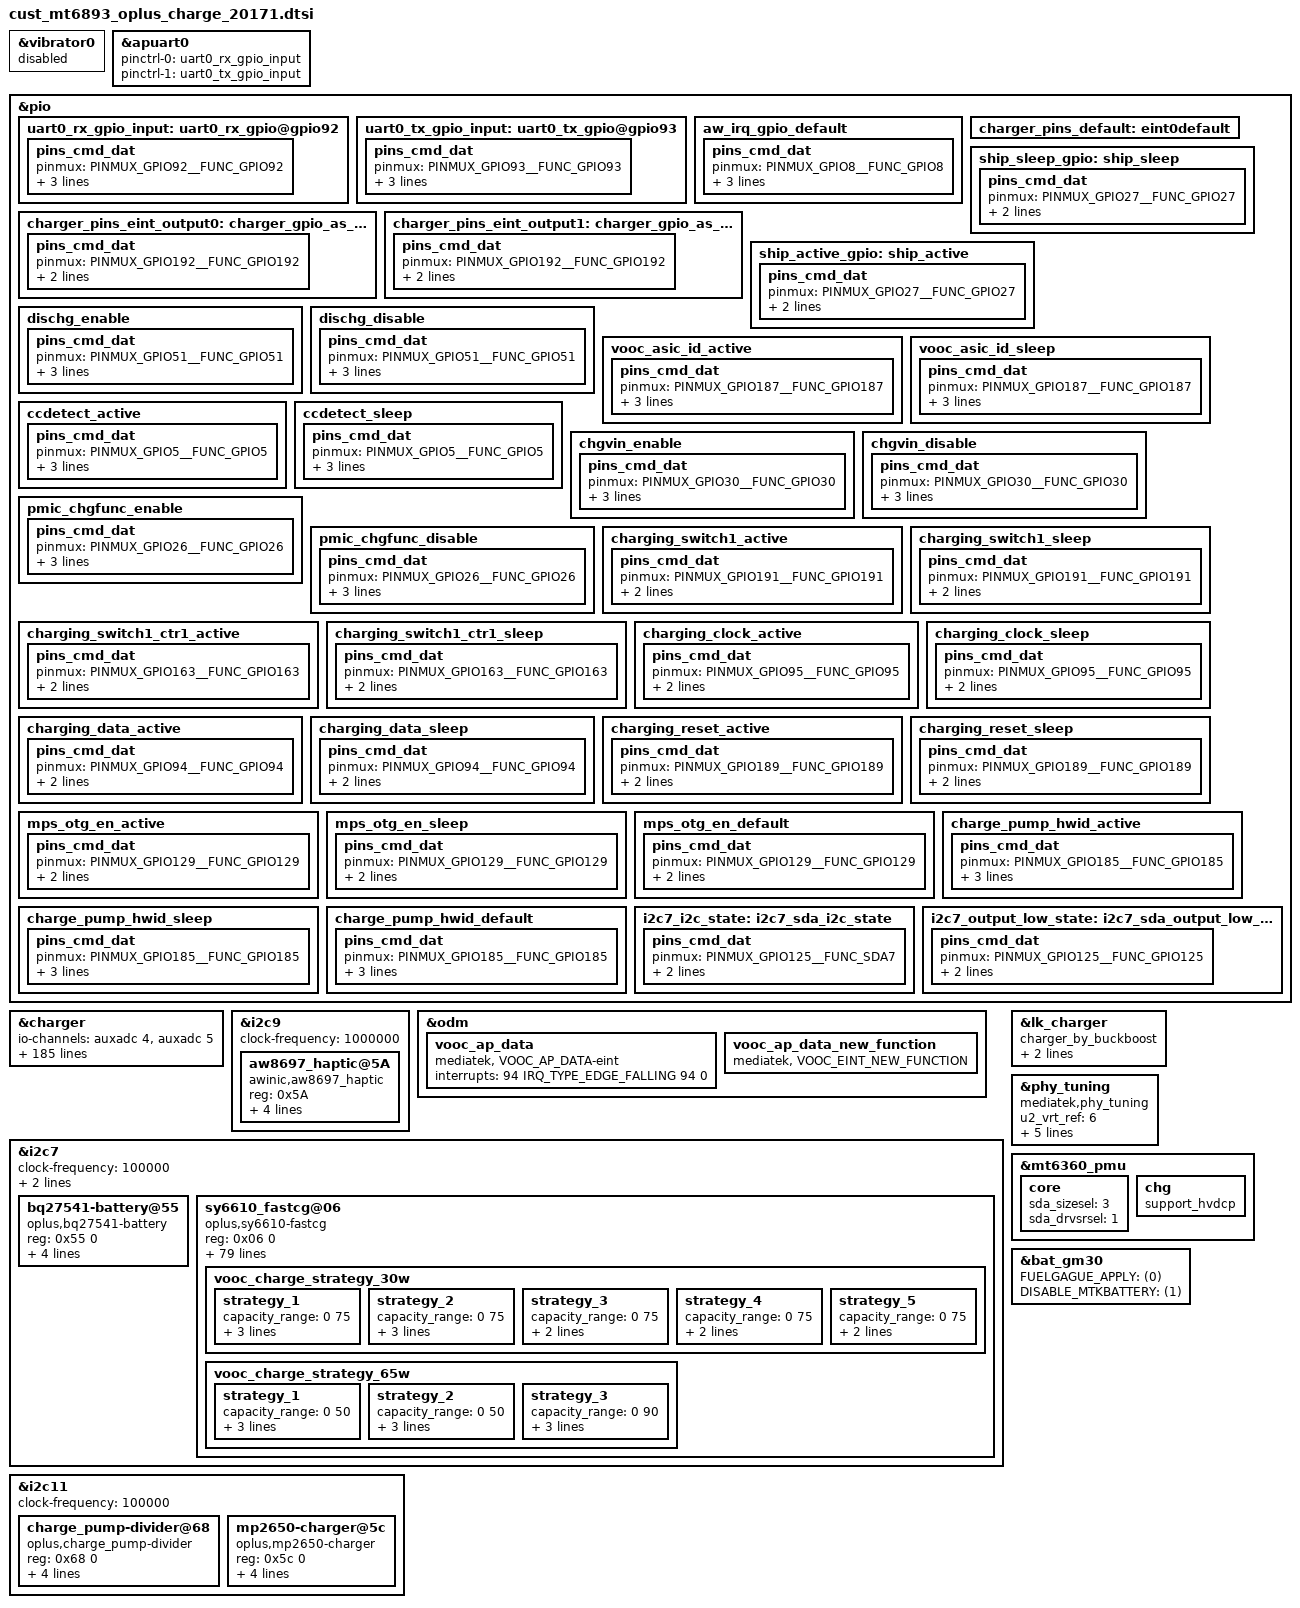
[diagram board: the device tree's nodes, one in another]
// SPDX-License-Identifier: GPL-2.0-only
/*
* Copyright (C) 2021-2020 Oplus. All rights reserved.
*/

/* charge start */
&vibrator0 {
	status = "disabled";
};

&apuart0 {
	pinctrl-names = "uart0_rx_gpio", "uart0_tx_gpio";
	pinctrl-0 = <&uart0_rx_gpio_input>;
	pinctrl-1 = <&uart0_tx_gpio_input>;
	status = "okay";
};

&pio {
	uart0_rx_gpio_input:uart0_rx_gpio@gpio92 {
		pins_cmd_dat {
			pinmux = <PINMUX_GPIO92__FUNC_GPIO92>;
			input-enable;
			slew-rate = <0>;
			bias-disable;
		};
	};

	uart0_tx_gpio_input:uart0_tx_gpio@gpio93 {
		pins_cmd_dat {
			pinmux = <PINMUX_GPIO93__FUNC_GPIO93>;
			input-enable;
			slew-rate = <0>;
			bias-disable;
		};
	};
};

&charger {
	io-channels = <&auxadc 4>,
		<&auxadc 5>;
	io-channel-names = "auxadc4-usb_temp_v_l",
		"auxadc5-usb_temp_v_r";

	pinctrl-names = "default", "charger_gpio_as_output_low", "charger_gpio_as_output_high", "ship_sleep", "ship_active",
		"dischg_enable", "dischg_disable", "chgvin_enable", "chgvin_disable", "pmic_chgfunc_enable", "pmic_chgfunc_disable",
		"ccdetect_active","ccdetect_sleep";
	pinctrl-0 = <&charger_pins_default>;
	pinctrl-1 = <&charger_pins_eint_output0>;		//USB_ON -> USB_SWITCH:(UART && USB)
	pinctrl-2 = <&charger_pins_eint_output1>;
	pinctrl-3 = <&ship_sleep_gpio>;
	pinctrl-4 = <&ship_active_gpio>;
	pinctrl-5 = <&dischg_enable>;
	pinctrl-6 = <&dischg_disable>;
	pinctrl-7 = <&chgvin_enable>;
	pinctrl-8 = <&chgvin_disable>;
	pinctrl-9 = <&pmic_chgfunc_enable>;
	pinctrl-10 = <&pmic_chgfunc_disable>;
	//pinctrl-5 = <&shortc_active_gpio>;
	pinctrl-11 = <&ccdetect_active>;
	pinctrl-12 = <&ccdetect_sleep>;

	qcom,hv_flashled_support;
	qcom,chargerid_support;
	qcom,smart_charging_screenoff;
	qcom,usbtemp_batttemp_gap = <18>;
	qcom,input_current_charger_ma = <2000>;
	qcom,pd_input_current_charger_ma = <2000>;
	qcom,qc_input_current_charger_ma = <2000>;
	qcom,input_current_usb_ma = <500>;

	qcom,input_current_led_ma = <1200>;
	qcom,input_current_led_ma_high = <1200>;
	qcom,input_current_led_ma_warm = <1500>;
	qcom,input_current_led_ma_normal = <2000>;
	qcom,led_warm_bat_decidegc = <350>;
	qcom,led_high_bat_decidegc = <370>;

	qcom,input_current_camera_ma = <1200>;
	qcom,input_current_cdp_ma = <1500>;

	qcom,input_current_vooc_led_ma_high = <1200>;
	qcom,input_current_vooc_led_ma_warm = <1800>;
	qcom,input_current_vooc_led_ma_normal = <3600>;
	qcom,input_current_vooc_ma_normal = <3600>;
	qcom,vooc_temp_bat_normal_decidegc = <350>;
	qcom,input_current_vooc_ma_warm = <3200>;
	qcom,vooc_temp_bat_warm_decidegc = <370>;
	qcom,input_current_vooc_ma_high = <2200>;
	qcom,vooc_temp_bat_hot_decidegc = <440>;

	qcom,charger_current_vooc_ma_normal = <1800>;

	qcom,chg_ctrl_by_calling;
	qcom,input_current_calling_ma = <1500>;

	qcom,overtemp_bat_decidegc = <350>;
	qcom,iterm_disabled = <0>;
	sw_full_count = <25>;
	qcom,iterm_ma = <120>;
	qcom,recharge-mv = <100>;
	qcom,batt_capacity_mah = <4500>;/*typical capacity*/

	qcom,removed_bat_decidegc = <190>;  /*<-19C*/

	qcom,cold_bat_decidegc = <20>;  /*-2C~0C*/
	qcom,temp_cold_vfloat_mv = <3980>;
	qcom,temp_cold_fastchg_current_ma = <300>;

	qcom,little_cold_bat_decidegc = <0>;    /*0C~5C*/
	qcom,temp_little_cold_vfloat_mv = <4435>;
	qcom,temp_little_cold_fastchg_current_ma_high = <1100>;
	qcom,temp_little_cold_fastchg_current_ma_low = <1100>;
	qcom,temp_little_cold_fastchg_current_ma = <1100>;
	qcom,pd_temp_little_cold_fastchg_current_ma_high = <2000>;
	qcom,pd_temp_little_cold_fastchg_current_ma_low = <1400>;
	qcom,qc_temp_little_cold_fastchg_current_ma_high = <2000>;
	qcom,qc_temp_little_cold_fastchg_current_ma_low = <1400>;

	qcom,cool_bat_decidegc = <50>;  /*5C~12C*/
	qcom,temp_cool_vfloat_mv = <4435>;
	qcom,temp_cool_fastchg_current_ma_high = <1100>;
	qcom,temp_cool_fastchg_current_ma_low = <1100>;
	qcom,pd_temp_cool_fastchg_current_ma_high = <2000>;
	qcom,pd_temp_cool_fastchg_current_ma_low = <2000>;
	qcom,qc_temp_cool_fastchg_current_ma_high = <2000>;
	qcom,qc_temp_cool_fastchg_current_ma_low = <2000>;

	qcom,little_cool_bat_decidegc = <120>;  /*12C~16C*/
	qcom,temp_little_cool_vfloat_mv = <4435>;
	qcom,temp_little_cool_fastchg_current_ma = <1100>;
	qcom,pd_temp_little_cool_fastchg_current_ma = <2000>;
	qcom,qc_temp_little_cool_fastchg_current_ma = <2000>;

	qcom,normal_bat_decidegc = <160>;       /*16C~45C*/
	qcom,temp_normal_vfloat_mv = <4435>;
	qcom,temp_normal_fastchg_current_ma = <1100>;
	qcom,pd_temp_normal_fastchg_current_ma = <2000>;
	qcom,qc_temp_normal_fastchg_current_ma = <2000>;

	qcom,warm_bat_decidegc = <450>;         /*45C~53C*/ /*8pin Bat Vooc project need add 3 degree C*/
	qcom,temp_warm_vfloat_mv = <4130>;
	qcom,temp_warm_fastchg_current_ma = <600>;
	qcom,pd_temp_warm_fastchg_current_ma = <600>;
	qcom,qc_temp_warm_fastchg_current_ma = <600>;
	qcom,temp_warm_fastchg_current_ma_led_on = <250>;

	qcom,hot_bat_decidegc = <530>;

	qcom,non_standard_vfloat_mv = <3980>;
	qcom,non_standard_fastchg_current_ma = <512>;

	qcom,short_c_bat_cv_mv = <4330>;
	qcom,short_c_bat_vfloat_mv = <3800>;
	qcom,short_c_bat_fastchg_current_ma = <512>;

	qcom,cold_vfloat_sw_limit = <3930>;
	qcom,little_cold_vfloat_sw_limit = <4385>;
	qcom,cool_vfloat_sw_limit = <4385>;
	qcom,little_cool_vfloat_sw_limit = <4385>;
	qcom,normal_vfloat_sw_limit = <4385>;
	qcom,warm_vfloat_sw_limit = <4080>;
	qcom,non_standard_vfloat_sw_limit = <3930>;
	qcom,short_c_bat_vfloat_sw_limit = <3750>;

	qcom,max_chg_time_sec = <63360>; // 2200 * 2 / 250 H
	qcom,charger_hv_thr = <9900>;
	qcom,charger_recv_thr = <9500>;
	qcom,charger_lv_thr = <3400>;
	qcom,vbatt_full_thr = <4435>;
	qcom,vbatt_hv_thr = <4600>;

	qcom,vfloat_step_mv = <8>;
	qcom,non_standard_vfloat_over_sw_limit = <3990>;
	qcom,cold_vfloat_over_sw_limit = <3990>;
	qcom,little_cold_vfloat_over_sw_limit = <4445>;
	qcom,cool_vfloat_over_sw_limit = <4445>;
	qcom,little_cool_vfloat_over_sw_limit = <4445>;
	qcom,normal_vfloat_over_sw_limit = <4445>;
	qcom,warm_vfloat_over_sw_limit = <4140>;

	qcom,vbatt_power_off = <3300>;
	qcom,vbatt_soc_1 = <3310>;
	qcom,vooc_project = <3>;
	qcom,vbatt_num = <2>;
	qcom,new_ui_warning_support;
	qcom,ffc_support;
	qcom,dual_ffc;
	recharge_after_full;

	qcom,normal_vterm_hw_inc = <18>;
	qcom,non_normal_vterm_hw_inc = <18>;

	qcom,ff1_normal_fastchg_ma = <550>;
	qcom,ff1_warm_fastchg_ma = <550>;

	qcom,ffc2_normal_fastchg_ma = <350>;/*12C~35c*/
	qcom,ffc2_temp_warm_decidegc = <350>;
	qcom,ffc2_warm_fastchg_ma = <350>;/*35C~40c*/
	qcom,ffc2_temp_high_decidegc = <400>;
	qcom,ffc2_temp_low_decidegc = <120>;

	qcom,ff1_exit_step_ma = <150>;
	qcom,ff1_warm_exit_step_ma = <150>;
	qcom,ffc2_exit_step_ma = <150>;
	qcom,ffc2_warm_exit_step_ma = <150>;

	qcom,ffc_normal_vfloat_sw_limit = <4445>;
	qcom,ffc_temp_normal_vfloat_mv = <4500>;
	qcom,ffc_normal_vfloat_over_sw_limit = <4500>;
	qcom,ffc_warm_vfloat_sw_limit = <4445>;
	qcom,ffc_temp_warm_vfloat_mv = <4500>;
	qcom,ffc_warm_vfloat_over_sw_limit = <4500>;

	qcom,ffc2_normal_vfloat_sw_limit = <4440>;
	qcom,ffc2_temp_normal_vfloat_mv = <4500>;
	qcom,ffc2_normal_vfloat_over_sw_limit = <4500>;
	qcom,ffc2_warm_vfloat_sw_limit = <4435>;
	qcom,ffc2_temp_warm_vfloat_mv = <4500>;
	qcom,ffc2_warm_vfloat_over_sw_limit = <4500>;

	qcom,default_iterm_ma = <120>;
	qcom,default_temp_normal_fastchg_current_ma = <1100>;
	qcom,default_normal_vfloat_sw_limit = <4385>;
	qcom,default_temp_normal_vfloat_mv = <4435>;
	qcom,default_normal_vfloat_over_sw_limit = <4445>;

	qcom,default_temp_little_cool_fastchg_current_ma = <1100>;
	qcom,default_little_cool_vfloat_sw_limit = <4385>;
	qcom,default_temp_little_cool_vfloat_mv = <4435>;
	qcom,default_little_cool_vfloat_over_sw_limit = <4445>;

	qcom,vooc_show_ui_soc_decimal;
	qcom,ui_soc_decimal_speedmin = <20>;//2A
	qcom,check_batt_full_by_sw;
	qcom,external_gauge;
	qcom,chg_ctrl_by_lcd;
	qcom,chg_ctrl_by_vooc;
	qcom,chg_ctrl_by_camera;
	qcom,support_ntc_01c_precision;
	qcom,sw_vfloat_over_protect_enable;

	qcom,support_abnormal_adapter;

	//for PD9V or QC9V
	qcom,vbatt_pdqc_to_5v_thr = <4100>;
	qcom,vbatt_pdqc_to_9v_thr = <4000>;

	//GPIO config:
	qcom,chargerid_switch-gpio = <&pio 192 0x00>;
	qcom,ship-gpio = <&pio 27 0x00>;
	qcom,dischg-gpio = <&pio 51 0x00>;
	//qcom,shortc-gpio = <&pio 121 0x00>;
	qcom,ccdetect-gpio = <&pio 5 0x00>;
	qcom,chgvin = <&pio 30 0x00>;
	qcom,pmic_chgfunc = <&pio 26 0x00>;
};

&i2c9 {
	status = "okay";
	clock-frequency = <1000000>;

	/* AWINIC AW8697 Haptic */
	aw8697_haptic@5A {
		status = "okay";
		compatible = "awinic,aw8697_haptic";
		reg = <0x5A>;
		reset-gpio = <&pio 110 0x00>;
		irq-gpio = <&pio 8 0x00>;
		qcom,device_id = <815>;

		pinctrl-names = "default";
		pinctrl-0 = <&aw_irq_gpio_default>;
	};
};

&pio{
	aw_irq_gpio_default: aw_irq_gpio_default {
		pins_cmd_dat {
			pinmux = <PINMUX_GPIO8__FUNC_GPIO8>;
			input-enable;
			slew-rate = <0>;
			bias-pull-up;
		};
	};
};

&odm {
	vooc_ap_data:vooc_ap_data {
		compatible = "mediatek, VOOC_AP_DATA-eint";
		interrupts = <94 IRQ_TYPE_EDGE_FALLING 94 0>;
	};
	vooc_ap_data_new_function:vooc_ap_data_new_function {
		compatible = "mediatek, VOOC_EINT_NEW_FUNCTION";
	};
};

&i2c7 {
	status = "okay";
	clock-frequency = <100000>;

	bq27541-battery@55 {
		status = "okay";
		compatible = "oplus,bq27541-battery";
		reg = <0x55 0>;
		qcom,modify-soc-smooth;
		qcom,modify-soc-calibration;
		qcom,batt_bq28z610;
		qcom,sha1_key_index = <1>;
		//qcom,bq28z610_need_balancing;
	};

	sy6610_fastcg@06{
		status = "okay";
		compatible = "oplus,sy6610-fastcg";
		reg = <0x06 0>;
		qcom,oplus_batt_4250mv;
		qcom,support_vooc_by_normal_charger_path;
		//qcom,vooc_fw_update_newmethod;
		qcom,vooc-fw-type = <3>;
		qcom,vooc_reply_mcu_bits = <7>;
		qcom,vooc-low-temp = <0>;
		qcom,vooc-high-temp = <430>;
		qcom,vooc-low-soc = <1>;
		qcom,vooc-high-soc = <90>;
		qcom,vooc-little-cool-temp = <160>;
		qcom,vooc-cool-temp = <120>;
		qcom,vooc-little-cool-to-normal-temp = <180>;
		qcom,vooc-normal-to-little-cool-current = <0x05>;//5A

		qcom,vooc_cool_bat_volt = <3450>;
		qcom,vooc_little_cool_bat_volt = <3400>;
		qcom,vooc_normal_bat_volt = <3350>;
		qcom,vooc_warm_bat_volt = <3300>;

		qcom,vooc_cool_bat_suspend_volt = <3450>;
		qcom,vooc_little_cool_bat_suspend_volt = <3400>;
		qcom,vooc_normal_bat_suspend_volt = <3350>;
		qcom,vooc_warm_bat_suspend_volt = <3300>;

		qcom,vooc_multistep_adjust_current_support;
		qcom,vooc_multistep_initial_batt_temp = <1000>;
		qcom,vooc_strategy_normal_current = <0x0c>;
		qcom,vooc_batt_over_high_temp = <440>;
		qcom,vooc_batt_over_low_temp = <45>;
		qcom,vooc_over_high_or_low_current = <0x0>;

		qcom,vooc_strategy1_batt_high_temp0 = <400>;
		qcom,vooc_strategy1_batt_high_temp1 = <420>;
		qcom,vooc_strategy1_batt_high_temp2 = <430>;
		qcom,vooc_strategy1_batt_low_temp2 = <420>;
		qcom,vooc_strategy1_batt_low_temp1 = <410>;
		qcom,vooc_strategy1_batt_low_temp0 = <390>;

		qcom,vooc_strategy1_high_current0 = <0x09>;  // 5A
		qcom,vooc_strategy1_high_current1 = <0x07>;  // 4A
		qcom,vooc_strategy1_high_current2 = <0x05>;  // 3A
		qcom,vooc_strategy1_low_current2 = <0x07>;   // 4A
		qcom,vooc_strategy1_low_current1 = <0x09>;   // 5A
		qcom,vooc_strategy1_low_current0 = <0x0c>;   // 0x0c

		qcom,vooc_strategy2_batt_up_temp1 = <375>;
		qcom,vooc_strategy2_batt_up_down_temp2 = <380>;
		qcom,vooc_strategy2_batt_up_temp3 = <390>;
		qcom,vooc_strategy2_batt_up_down_temp4 = <400>;
		qcom,vooc_strategy2_batt_up_temp5 = <410>;
		qcom,vooc_strategy2_batt_up_temp6 = <415>;
		qcom,vooc_strategy2_high0_current = <0x09>;
		qcom,vooc_strategy2_high1_current = <0x07>;
		qcom,vooc_strategy2_high2_current = <0x05>;
		qcom,vooc_strategy2_high3_current = <0x03>;

		qcom,abnormal_adapter_current = <0x00 0x00 0x09 0x09 0x07 0x07 0x05 0x05 0x03 0x03>;

		qcom,vooc_current_lvl = <1000
									1500
									2000
									2500
									3000
									3500
									4000
									4500
									5000
									5500
									6000
									6500
									7000
									7500
									8000
									8500
									9000
									9500
									10000
									10500
									11000
									11500
									12000
									12500>;
		pinctrl-names = "switch1_act_switch2_act", "switch1_sleep_switch2_sleep",
						"switch1_act_switch3_act", "switch1_sleep_switch3_sleep",
						"switch1_act_switch2_sleep", "switch1_sleep_switch2_act",
						"clock_active","clock_sleep",
						"data_active","data_sleep",
						"reset_active","reset_sleep",
						"charging_switch1_ctr1_active","charging_switch1_ctr1_sleep",
						"vooc_asic_id_active","vooc_asic_id_sleep";
		pinctrl-0 = <&charging_switch1_active>;
		pinctrl-1 = <&charging_switch1_sleep>;
		pinctrl-2 = <&charging_switch1_active>;
		pinctrl-3 = <&charging_switch1_sleep>;
		pinctrl-4 = <&charging_switch1_active>;
		pinctrl-5 = <&charging_switch1_sleep>;
		pinctrl-6 = <&charging_clock_active>;
		pinctrl-7 = <&charging_clock_sleep>;
		pinctrl-8 = <&charging_data_active>;
		pinctrl-9 = <&charging_data_sleep>;
		pinctrl-10 = <&charging_reset_active>;
		pinctrl-11 = <&charging_reset_sleep>;
		pinctrl-12 = <&charging_switch1_ctr1_active>;
		pinctrl-13 = <&charging_switch1_ctr1_sleep>;
		pinctrl-14 = <&vooc_asic_id_active>;
		pinctrl-15 = <&vooc_asic_id_sleep>;

		qcom,charging_switch1-gpio = <&pio 191 0x00>;
		qcom,charging_switch1_ctr1-gpio = <&pio 163 0x00>;
		//qcom,charging_switch2-gpio = <&tlmm 113 0x00>;
		//qcom,charging_switch3-gpio = <&tlmm 38 0x00>;

		qcom,charging_reset-gpio = <&pio 189 0x00>;
		qcom,charging_clock-gpio = <&pio 95 0x00>;
		qcom,charging_data-gpio = <&pio 94 0x00>;
		qcom,vooc_asic_id-gpio = <&pio 187 0x00>;

		qcom,parse_fw_from_dt;
		vooc,firmware_data = [
			20 05 00 20 d5 00 00 00 cb 02 00 00 f5 01 00 00
			00 00 00 00 00 00 00 00 00 00 00 00 00 00 00 00
			00 00 00 00 00 00 00 00 00 00 00 00 e1 00 00 00
			00 00 00 00 00 00 00 00 e3 00 00 00 cd 03 00 00
			e7 00 00 00 e9 00 00 00 eb 00 00 00 ed 00 00 00
			ef 00 00 00 f1 00 00 00 f3 00 00 00 f5 00 00 00
			d9 23 00 00 ed 23 00 00 fb 00 00 00 fd 00 00 00
			ff 00 00 00 01 01 00 00 03 01 00 00 89 2c 00 00
			07 01 00 00 25 1f 00 00 91 24 00 00 4d 2e 00 00
			0f 01 00 00 11 01 00 00 13 01 00 00 15 01 00 00
			17 01 00 00 19 01 00 00 1d 01 00 00 1d 01 00 00
			1f 01 00 00 21 01 00 00 23 01 00 00 25 01 00 00
			03 48 85 46 00 f0 84 f8 00 48 00 47 59 25 00 00
			20 05 00 20 14 48 80 47 14 48 00 47 fe e7 fe e7
			fe e7 fe e7 fe e7 fe e7 fe e7 fe e7 fe e7 fe e7
			fe e7 fe e7 fe e7 fe e7 fe e7 fe e7 fe e7 fe e7
			fe e7 fe e7 fe e7 fe e7 fe e7 fe e7 fe e7 fe e7
			fe e7 fe e7 fe e7 fe e7 fe e7 fe e7 fe e7 fe e7
			fe e7 fe e7 fe e7 00 00 e5 03 00 00 c1 00 00 00
			30 b5 0b 46 01 46 00 20 20 22 01 24 09 e0 0d 46
			d5 40 9d 42 05 d3 1d 46 95 40 49 1b 25 46 95 40
			40 19 15 46 52 1e 00 2d f1 dc 30 bd 70 b5 00 24
			25 46 00 28 01 da 01 24 40 42 00 29 01 da 01 25
			49 42 ff f7 dd ff ac 42 00 d0 40 42 00 2c 00 d0
			49 42 70 bd d2 b2 01 e0 02 70 40 1c 49 1e fb d2
			70 47 00 22 f6 e7 10 b5 13 46 0a 46 04 46 19 46
			ff f7 f0 ff 20 46 10 bd 03 21 00 1d 40 1e 03 78
			12 02 1a 43 49 1e f9 d5 10 46 70 47 03 46 03 22
			08 70 00 0a 49 1c 52 1e fa d5 18 46 70 47 00 00
			06 4c 01 25 06 4e 05 e0 e3 68 07 cc 2b 43 0c 3c
			98 47 10 34 b4 42 f7 d3 ff f7 6e ff 78 34 00 00
			98 34 00 00 04 20 71 46 08 42 02 d1 ef f3 08 80
			01 e0 ef f3 09 80 00 00 00 4a 10 47 8d 02 00 00
			00 20 03 49 09 68 01 22 12 03 11 40 08 0b 70 47
			00 00 01 40 10 b5 01 f0 cf fe 04 46 10 20 20 40
			00 28 17 d0 04 20 01 f0 91 fe 10 48 00 68 00 28
			07 d1 02 f0 93 fe 00 20 0d 49 08 70 01 20 0b 49
			08 60 0c 48 00 78 02 28 02 d1 00 f0 4d fc 01 e0
			01 f0 0c f8 01 20 80 02 20 40 00 28 05 d0 0a 20
			01 f0 74 fe 01 20 04 49 08 70 10 bd a0 00 00 20
			64 00 00 20 8b 00 00 20 3d 00 00 20 00 bf fe e7
			f8 b5 04 46 0d 46 16 46 33 46 2a 46 21 46 55 20
			01 f0 b4 fe 07 46 38 46 f8 bd f8 b5 05 46 14 46
			20 78 61 78 09 02 08 43 06 46 32 46 29 46 55 20
			01 f0 a0 ff 07 46 38 46 f8 bd 70 47 00 bf 72 b6
			00 bf 05 48 00 69 01 21 09 03 88 43 02 49 08 61
			00 bf 62 b6 00 bf 70 47 00 00 01 40 06 48 40 68
			01 21 09 03 88 43 04 49 48 60 08 46 00 69 89 14
			08 43 01 49 08 61 70 47 00 00 01 40 00 bf 72 b6
			00 bf 05 48 00 69 01 21 09 03 88 43 02 49 08 61
			00 bf 62 b6 00 bf 70 47 00 00 01 40 03 48 00 69
			01 21 09 03 88 43 01 49 08 61 70 47 00 00 01 40
			00 bf 72 b6 00 bf 05 48 00 69 01 21 c9 02 88 43
			02 49 08 61 00 bf 62 b6 00 bf 70 47 00 00 01 40
			00 bf 72 b6 00 bf 08 48 40 68 01 21 c9 02 88 43
			05 49 48 60 08 46 00 69 c9 14 08 43 02 49 08 61
			00 bf 62 b6 00 bf 70 47 00 00 01 40 06 48 40 68
			01 21 c9 02 88 43 04 49 48 60 08 46 00 69 c9 14
			08 43 01 49 08 61 70 47 00 00 01 40 00 bf 72 b6
			00 bf 05 48 00 69 01 21 c9 02 88 43 02 49 08 61
			00 bf 62 b6 00 bf 70 47 00 00 01 40 04 48 00 68
			00 28 04 d0 02 48 00 68 40 1e 01 49 08 60 70 47
			ac 00 00 20 70 47 00 00 10 b5 37 48 00 88 00 28
			05 d0 35 48 00 88 40 1e 33 49 08 80 15 e0 7d 20
			c0 00 31 49 08 80 31 48 00 88 00 28 04 d0 2f 48
			00 88 40 1e 2d 49 08 80 2d 48 00 88 00 28 04 d0
			2b 48 00 88 40 1e 2a 49 08 80 2a 48 00 68 00 28
			04 d0 28 48 00 68 40 1e 26 49 08 60 26 48 00 68
			00 28 04 d0 24 48 00 68 40 1e 23 49 08 60 23 48
			00 68 00 28 04 d0 21 48 00 68 40 1e 1f 49 08 60
			1f 48 00 78 00 28 04 d0 1d 48 00 78 40 1e 1c 49
			08 70 1c 48 00 68 00 28 04 d0 1a 48 00 68 40 1e
			18 49 08 60 18 48 00 68 00 28 04 d0 16 48 00 68
			40 1e 15 49 08 60 15 48 00 78 40 1c 13 49 08 70
			08 46 00 78 c8 28 0e dd 00 20 08 70 10 48 00 78
			00 28 05 d0 00 20 01 f0 a9 fc 01 20 0d 49 08 70
			01 20 0b 49 08 70 10 bd 66 00 00 20 68 00 00 20
			6a 00 00 20 6c 00 00 20 70 00 00 20 74 00 00 20
			78 00 00 20 7c 00 00 20 80 00 00 20 64 00 00 20
			50 00 00 20 3c 00 00 20 30 b4 74 46 64 1e 25 78
			64 1c ab 42 04 d3 63 5d 5b 00 e3 18 30 bc 18 47
			1d 46 f8 e7 00 28 05 db c2 06 d2 0e 01 21 91 40
			01 4a 11 60 70 47 00 00 00 e1 00 e0 10 b5 00 28
			19 db 1a 4a 03 23 1b 02 d2 18 83 08 9b 00 d2 58
			83 07 dc 0e ff 23 a3 40 9a 43 8b 07 1b 0e 84 07
			e4 0e a3 40 1a 43 11 4b 03 24 24 02 1b 19 84 08
			a4 00 1a 51 18 e0 0e 4a 03 07 1b 0f 08 3b 9b 08
			9b 00 d2 58 83 07 dc 0e ff 23 a3 40 9a 43 8b 07
			1b 0e 84 07 e4 0e a3 40 1a 43 05 4b 04 07 24 0f
			08 3c a4 08 a4 00 1a 51 10 bd 00 00 00 e1 00 e0
			1c ed 00 e0 10 b5 00 28 19 db 1a 4a 03 23 1b 02
			d2 18 83 08 9b 00 d2 58 83 07 dc 0e ff 23 a3 40
			9a 43 8b 07 1b 0e 84 07 e4 0e a3 40 1a 43 11 4b
			03 24 24 02 1b 19 84 08 a4 00 1a 51 18 e0 0e 4a
			03 07 1b 0f 08 3b 9b 08 9b 00 d2 58 83 07 dc 0e
			ff 23 a3 40 9a 43 8b 07 1b 0e 84 07 e4 0e a3 40
			1a 43 05 4b 04 07 24 0f 08 3c a4 08 a4 00 1a 51
			10 bd 00 00 00 e1 00 e0 1c ed 00 e0 02 e0 08 c8
			12 1f 08 c1 00 2a fa d1 70 47 70 47 00 20 01 e0
			01 c1 12 1f 00 2a fb d1 70 47 00 00 30 b5 42 68
			0d 4c d5 02 23 46 10 33 e2 68 00 2d 09 da d3 5c
			43 67 52 1c e2 60 03 22 0a 70 01 21 61 70 89 1e
			07 e0 05 6f d5 54 e2 68 52 1c e2 60 04 22 0a 70
			11 04 41 60 00 20 30 bd f0 00 00 20 10 b5 42 68
			12 03 0a d5 08 4c 23 46 e2 68 10 33 d3 5c 43 67
			52 1c e2 60 01 22 d2 04 42 60 40 68 c0 01 01 d5
			05 20 08 70 00 20 10 bd f0 00 00 20 70 b5 42 68
			05 24 52 03 00 2a 16 da 0e 4b da 68 04 2a 0a d2
			05 6f 1e 46 10 36 95 55 da 68 52 1c da 60 01 22
			92 04 42 60 07 e0 08 4a 55 6f 96 15 35 43 55 67
			0c 70 02 22 5a 70 40 68 c0 01 00 d5 0c 70 00 20
			70 bd 00 00 f0 00 00 20 00 c0 00 40 70 b5 42 68
			0d 4b 0e 4c 52 03 08 d5 05 6f 62 68 9e 18 35 72
			52 1c 62 60 01 22 92 04 42 60 58 68 62 68 90 42
			07 d1 02 20 08 70 00 20 60 60 05 49 18 69 40 18
			18 61 00 20 70 bd 00 00 f0 00 00 20 0c 00 00 20
			02 02 02 02 42 68 d2 02 03 d5 00 21 c9 43 41 60
			07 e0 42 68 52 03 06 d5 01 22 92 04 42 60 01 20
			08 70 00 20 70 47 01 20 70 47 00 00 00 b5 40 68
			0b 46 c0 01 06 d5 01 f0 ad fe 00 20 02 49 18 70
			48 70 c8 60 02 20 00 bd f0 00 00 20 f8 b5 05 46
			0f 46 ff f7 0b fe 07 26 3c e0 00 24 00 bf 72 b6
			00 bf ff f7 c3 fd 09 e0 4b 20 80 01 84 42 04 d3
			ff f7 fc fd ff f7 aa fd f8 bd 64 1c ff f7 28 fd
			00 28 f1 d0 00 bf 00 20 31 49 09 68 01 22 d2 02
			11 40 c8 0a 00 bf b0 40 29 78 08 43 28 70 ff f7
			85 fd 00 bf 62 b6 00 bf 00 bf 00 bf 00 bf 00 bf
			00 bf 00 bf 00 bf 00 bf 00 bf 00 bf 00 bf 00 bf
			00 bf 00 bf 00 bf 00 bf 00 bf 00 bf 00 bf 00 bf
			00 bf 76 1e 00 2e c0 da 00 2f 02 d0 ff f7 90 fd
			11 e0 ff f7 9d fd 00 bf 00 bf 00 bf 72 b6 00 bf
			17 48 00 69 01 21 c9 02 08 43 15 49 08 61 00 bf
			62 b6 00 bf 00 bf 00 f0 2d ff 00 f0 2b ff 00 24
			00 bf 72 b6 00 bf ff f7 69 fd 09 e0 4b 20 80 01
			84 42 04 d3 ff f7 a2 fd ff f7 50 fd a4 e7 64 1c
			ff f7 ce fc 00 28 f1 d0 ff f7 38 fd 00 bf 62 b6
			00 bf 00 f0 0f ff 00 f0 0d ff 00 bf 94 e7 00 00
			00 00 01 40 f8 b5 07 46 00 f0 f4 fe 07 25 33 e0
			00 bf 72 b6 00 bf 01 20 a8 40 38 40 00 28 09 d0
			00 bf 34 48 00 69 01 21 c9 02 88 43 31 49 08 61
			00 bf 01 e0 ff f7 62 fd 00 24 00 bf 2d 48 00 69
			01 21 09 03 88 43 2b 49 08 61 00 bf 0a e0 4b 20
			80 01 84 42 05 d3 ff f7 61 fd ff f7 0f fd 01 20
			f8 bd 64 1c ff f7 8c fc 00 28 f0 d0 ff f7 f6 fc
			00 bf 62 b6 00 bf 6d 1e 00 2d c9 da ff f7 4e fd
			00 bf 00 bf 00 bf 00 bf 00 bf 00 bf 00 bf 00 bf
			00 bf 00 bf 00 bf 00 bf 00 f0 bc fe 00 f0 ba fe
			00 24 00 bf 72 b6 00 bf ff f7 f8 fc 0a e0 4b 20
			80 01 84 42 05 d3 ff f7 31 fd ff f7 df fc 01 20
			ce e7 64 1c ff f7 5c fc 00 28 f0 d0 00 bf 01 20
			08 49 09 68 c2 02 11 40 c8 0a 00 bf 06 46 ff f7
			bd fc 00 bf 62 b6 00 bf 00 f0 94 fe 00 f0 92 fe
			30 46 b5 e7 00 00 01 40 10 b5 ff f7 9f fc 00 bf
			00 bf 00 bf 00 bf 00 bf 00 bf 00 bf 00 bf 00 bf
			00 bf 00 bf 00 bf 00 bf 00 bf 00 bf 00 bf 00 bf
			00 bf 00 bf 00 bf 00 bf 72 b6 00 bf ff f7 e6 fc
			00 bf 00 bf 00 bf 00 bf 00 bf 00 bf 00 bf 00 bf
			00 bf 00 bf 00 bf 00 bf ff f7 88 fc 00 bf 62 b6
			00 bf 10 bd 10 b5 00 bf 72 b6 00 bf ff f7 ce fc
			00 bf 00 bf 00 bf 00 bf 00 bf 00 bf 00 bf 00 bf
			00 bf 00 bf 00 bf ff f7 71 fc 00 bf 62 b6 00 bf
			10 bd 00 00 10 b5 00 24 ff f7 a2 fc 00 bf 00 bf
			00 bf 00 bf 00 bf 00 bf 00 bf 00 bf 00 bf 00 bf
			00 bf 00 bf ff f7 4a fc 09 e0 4b 20 80 01 84 42
			04 d3 ff f7 b3 fc ff f7 61 fc 10 bd 64 1c 00 bf
			00 20 00 bf 00 bf 72 b6 00 bf 12 49 09 68 01 22
			12 03 11 40 08 0b 00 bf 62 b6 00 bf 00 28 e4 d0
			00 bf 00 bf 00 bf 00 bf 00 bf 00 bf 00 bf 00 bf
			00 bf 00 bf 00 bf 00 bf 00 bf 00 bf 00 bf 00 bf
			00 bf 00 bf 00 bf 00 bf 00 bf ff f7 51 fc 00 bf
			d3 e7 00 00 00 00 01 40 10 b5 00 20 11 49 89 69
			03 22 12 02 91 43 02 02 03 23 1b 02 1a 40 11 43
			0c 4a 91 61 00 bf 02 21 04 20 01 f0 31 fc 00 20
			08 49 89 69 03 22 92 02 91 43 82 02 03 23 9b 02
			1a 40 11 43 03 4a 91 61 00 bf 02 21 05 20 01 f0
			1f fc 10 bd 00 00 01 40 10 b5 fe 48 00 78 08 28
			0b da 01 f0 cb f9 fc 49 fa 4a 12 78 88 54 f9 48
			00 78 40 1c f7 49 08 70 10 bd f6 48 00 78 08 28
			29 d1 09 20 f3 49 08 70 02 f0 2e f9 f2 48 00 78
			01 28 21 d1 f0 48 40 78 00 28 1d d1 ee 48 80 78
			01 28 19 d1 ec 48 c0 78 c0 00 eb 49 09 79 89 00
			08 43 e9 49 49 79 49 00 08 43 e7 49 89 79 08 43
			e6 49 08 70 00 20 e6 49 08 70 e6 48 00 78 00 28
			d6 d1 e5 49 08 70 8f e0 df 48 00 78 01 28 20 d1
			dd 48 40 78 00 28 1c d1 db 48 80 78 00 28 18 d1
			d9 48 c0 78 c0 00 d8 49 09 79 89 00 08 43 d6 49
			49 79 49 00 08 43 d4 49 89 79 08 43 d3 49 08 70
			00 20 d3 49 08 70 d3 49 08 70 02 20 d2 49 08 70
			6a e0 cd 48 40 78 01 28 21 d1 cb 48 80 78 00 28
			1d d1 c9 48 c0 78 01 28 19 d1 c7 48 00 79 c0 00
			c5 49 49 79 89 00 08 43 c3 49 89 79 49 00 08 43
			c1 49 c9 79 08 43 c1 49 08 70 00 20 c0 49 08 70
			c0 48 00 78 00 28 01 d1 bf 49 08 70 84 e7 ba 48
			40 78 01 28 20 d1 b8 48 80 78 00 28 1c d1 b6 48
			c0 78 00 28 18 d1 b4 48 00 79 c0 00 b2 49 49 79
			89 00 08 43 b0 49 89 79 49 00 08 43 ae 49 c9 79
			08 43 ae 49 08 70 00 20 ad 49 08 70 ad 49 08 70
			02 20 ad 49 08 70 5f e7 a7 48 c0 78 c0 00 a6 49
			09 79 89 00 08 43 a4 49 49 79 49 00 08 43 a2 49
			89 79 08 43 a1 49 08 70 02 20 a3 49 08 70 a0 48
			00 78 00 28 05 d1 9e 48 00 78 40 1c 9c 49 08 70
			02 e0 01 20 9d 49 08 70 9d 48 00 78 00 28 14 d1
			9c 49 c8 70 08 71 48 71 88 71 c8 71 08 72 48 72
			99 48 00 78 02 28 09 d1 90 48 00 78 00 07 00 0e
			96 49 08 70 01 20 93 49 48 71 3e e2 92 48 00 78
			01 28 0a d1 91 48 00 78 88 49 09 78 08 43 8f 49
			08 70 01 20 8b 49 48 71 2f e2 8d 48 00 78 05 28
			16 d1 88 48 80 7a 87 49 c8 70 08 46 c0 7a 08 71
			08 46 00 7b 48 71 08 46 40 7b 88 71 08 46 80 7b
			c8 71 08 46 c0 7b 08 72 08 46 00 7c 48 72 14 e2
			7f 48 00 78 04 28 09 d1 74 48 00 78 00 07 00 0c
			7c 49 08 80 01 20 77 49 48 71 06 e2 78 48 00 78
			03 28 0b d1 6d 48 00 78 00 02 76 49 09 88 08 43
			74 49 08 80 01 20 6f 49 48 71 f6 e1 70 48 00 78
			02 28 0b d1 65 48 00 78 00 01 6e 49 09 88 08 43
			6c 49 08 80 01 20 67 49 48 71 e6 e1 68 48 00 78
			01 28 15 d1 67 48 00 88 5c 49 09 78 08 43 65 49
			08 80 00 f0 9d fb 01 20 5e 49 48 71 62 48 00 88
			60 49 09 88 88 42 90 d1 01 20 60 49 08 70 cc e1
			5f 48 00 78 00 28 4c d0 5d 48 00 78 40 1e c1 00
			08 1a 5c 49 09 68 08 5c 52 49 c8 70 58 48 00 78
			40 1e c1 00 08 1a 57 49 09 68 40 18 40 78 4d 49
			08 71 53 48 00 78 40 1e c1 00 08 1a 51 49 09 68
			40 18 80 78 47 49 48 71 4d 48 00 78 40 1e c1 00
			08 1a 4c 49 09 68 40 18 c0 78 42 49 88 71 48 48
			00 78 40 1e c1 00 08 1a 46 49 09 68 40 18 00 79
			3c 49 c8 71 42 48 00 78 40 1e c1 00 08 1a 41 49
			09 68 40 18 40 79 37 49 08 72 3d 48 00 78 40 1e
			c1 00 08 1a 3b 49 09 68 40 18 80 79 31 49 48 72
			7b e1 2a 48 00 78 09 28 0c d1 00 20 2e 49 08 70
			2f 49 08 70 32 49 08 70 00 f0 d0 ff 01 20 32 49
			08 70 51 e6 00 20 28 49 08 70 29 49 08 70 2c 49
			08 70 1e 48 00 78 03 00 ff f7 36 fb 10 f3 09 84
			9e d4 e7 20 20 20 20 20 20 f4 f1 f0 ef 20 27 48
			00 78 00 28 13 d0 26 48 00 78 00 28 06 d1 01 20
			18 49 c8 70 08 71 08 72 48 72 02 e0 01 20 15 49
			88 71 1f 48 00 78 c0 43 1d 49 08 70 3c e1 1d 48
			00 78 00 28 38 d0 01 20 0e 49 c8 70 08 71 48 71
			88 71 c8 71 08 72 48 72 16 48 00 78 40 1e 15 49
			08 70 29 e1 4d 00 00 20 45 00 00 20 4f 00 00 20
			41 00 00 20 8c 00 00 20 8b 00 00 20 3e 00 00 20
			4e 00 00 20 04 01 00 20 51 00 00 20 52 00 00 20
			54 00 00 20 58 00 00 20 5a 00 00 20 5c 00 00 20
			55 00 00 20 2c 00 00 20 44 00 00 20 63 00 00 20
			8a 00 00 20 84 00 00 20 ad 48 00 68 ad 49 88 42
			01 da 00 24 07 e0 aa 49 09 68 aa 4a 88 1a 0a 21
			ff f7 fc f8 04 46 60 06 c0 0f a7 49 c8 70 a0 06
			c0 0f 08 71 e0 06 c0 0f 48 71 20 07 c0 0f 88 71
			60 07 c0 0f c8 71 a0 07 c0 0f 08 72 e0 07 c0 0f
			48 72 d9 e0 00 21 08 46 02 f0 aa f9 9b 49 08 70
			08 46 00 78 02 28 03 d1 01 20 97 49 08 71 0a e0
			96 48 00 78 01 28 03 d1 93 49 08 71 48 71 02 e0
			01 20 91 49 48 71 bf e0 01 20 91 49 08 70 91 48
			00 78 40 06 c0 0f 8c 49 c8 70 8e 48 00 78 80 06
			c0 0f 08 71 8b 48 00 78 c0 06 c0 0f 48 71 89 48
			00 78 00 07 c0 0f 88 71 86 48 00 78 40 07 c0 0f
			c8 71 84 48 00 78 80 07 c0 0f 08 72 81 48 00 78
			c0 07 c0 0f 48 72 00 20 7f 49 08 70 7d 48 00 78
			64 21 48 43 ff 30 2d 30 7c 49 08 80 0a 20 7c 49
			08 70 89 e0 7b 48 00 78 00 28 07 d0 00 20 7a 49
			08 70 78 48 00 78 40 1e 76 49 08 70 76 48 00 78
			6d 49 c8 70 01 20 48 71 76 e0 03 20 73 49 08 70
			01 20 69 49 08 71 88 71 6e e0 35 e0 33 e0 19 e0
			00 e0 2f e0 6e 48 00 78 00 28 03 d0 6d 48 00 78
			00 28 00 d1 60 e0 6a 48 00 78 40 1e 68 49 08 70
			06 20 69 49 08 70 00 f0 20 ff 68 49 08 70 00 f0
			bd f9 51 e0 66 48 00 78 40 1c 66 49 08 70 64 48
			00 78 80 1c 64 49 08 70 64 48 00 78 52 49 c8 70
			63 48 00 78 08 71 63 48 00 78 48 71 62 48 00 78
			88 71 39 e0 01 e0 00 e0 00 bf 60 48 00 78 00 28
			2f d0 4b 48 00 78 00 28 2b d0 5d 48 00 78 03 28
			03 d1 01 20 5b 49 08 70 0e e5 59 48 00 78 40 1c
			57 49 08 70 3e 49 09 68 3e 4a 88 1a 0a 21 ff f7
			25 f8 04 46 60 06 c0 0f 3b 49 c8 70 a0 06 c0 0f
			08 71 e0 06 c0 0f 48 71 20 07 c0 0f 88 71 60 07
			c0 0f c8 71 a0 07 c0 0f 08 72 e0 07 c0 0f 48 72
			02 e0 01 f0 df fe e7 e4 00 bf 2f 49 46 4a 12 78
			88 5c 01 f0 23 fe 44 48 00 78 40 1c 42 49 08 70
			08 46 00 78 09 28 49 dd 04 20 00 f0 c3 fa 01 f0
			05 fe 00 20 3c 49 08 70 3c 49 08 70 3c 49 08 70
			2a 48 00 78 00 28 05 d0 28 48 00 78 40 1e 27 49
			08 70 33 e0 28 48 00 78 00 28 05 d0 26 48 00 78
			40 1e 25 49 08 70 29 e0 26 48 00 78 00 28 0a d0
			24 48 00 78 40 1e 23 49 08 70 23 48 00 78 40 1e
			21 49 08 70 1a e0 2b 48 00 78 02 28 02 d0 04 28
			13 d1 0a e0 0d 48 00 78 01 28 05 d1 12 48 00 78
			01 28 01 d1 00 f0 12 fe 07 e0 01 20 11 49 08 70
			00 f0 73 fe 20 49 08 70 00 bf 00 bf 00 bf 8b e4
			38 00 00 20 4c 0d 00 00 04 01 00 20 98 00 00 20
			40 00 00 20 85 00 00 20 84 00 00 20 8e 00 00 20
			90 00 00 20 8c 00 00 20 43 00 00 20 51 00 00 20
			53 00 00 20 60 00 00 20 54 00 00 20 62 00 00 20
			30 00 00 20 55 00 00 20 56 00 00 20 32 00 00 20
			33 00 00 20 34 00 00 20 35 00 00 20 93 00 00 20
			42 00 00 20 3f 00 00 20 4e 00 00 20 4d 00 00 20
			50 00 00 20 4f 00 00 20 61 00 00 20 10 b5 5d 48
			00 78 08 28 0b da 00 f0 09 fe 5b 49 59 4a 12 78
			88 54 58 48 00 78 40 1c 56 49 08 70 10 bd 55 48
			00 78 08 28 61 d1 09 20 52 49 08 70 01 f0 6c fd
			51 48 00 78 01 28 1b d1 4f 48 40 78 00 28 17 d1
			4d 48 80 78 01 28 13 d1 4b 48 c0 78 c0 00 4a 49
			09 79 89 00 08 43 48 49 49 79 49 00 08 43 46 49
			89 79 08 43 45 49 08 70 00 20 45 49 08 70 3c e0
			41 48 40 78 01 28 1b d1 3f 48 80 78 00 28 17 d1
			3d 48 c0 78 01 28 13 d1 3b 48 00 79 c0 00 3a 49
			49 79 89 00 08 43 38 49 89 79 49 00 08 43 36 49
			c9 79 08 43 35 49 08 70 00 20 35 49 08 70 b5 e7
			31 48 c0 78 c0 00 30 49 09 79 89 00 08 43 2e 49
			49 79 49 00 08 43 2c 49 89 79 08 43 2b 49 08 70
			2b 48 00 78 00 28 05 d1 29 48 00 78 40 1c 28 49
			08 70 02 e0 01 20 27 49 08 70 27 48 00 78 00 28
			22 d1 01 20 25 49 88 70 00 20 c8 70 08 71 48 71
			88 71 c8 71 08 72 48 72 1c 48 00 78 04 28 02 d0
			06 28 0c d1 07 e0 1e 48 00 78 1c 49 c8 70 01 20
			c8 71 48 72 07 e0 01 20 18 49 c8 70 03 e0 01 20
			18 49 08 70 72 e7 00 bf 14 49 13 4a 12 78 88 5c
			01 f0 ec fc 10 48 00 78 40 1c 0f 49 08 70 08 46
			00 78 09 28 0b dd 04 20 00 f0 8c f9 01 f0 ce fc
			00 20 09 49 08 70 03 49 08 70 0b 49 08 70 00 bf
			54 e7 00 00 4d 00 00 20 45 00 00 20 4f 00 00 20
			41 00 00 20 3e 00 00 20 4e 00 00 20 04 01 00 20
			43 00 00 20 3f 00 00 20 50 00 00 20 28 48 00 78
			40 02 28 49 09 78 49 00 08 43 27 49 08 80 24 48
			00 78 40 06 c0 0f 25 49 48 71 21 48 00 78 80 06
			c0 0f c8 72 1e 48 00 78 c0 06 c0 0f 08 72 1c 48
			00 78 00 07 c0 0f 08 74 19 48 00 78 40 07 c0 0f
			88 73 17 48 00 78 80 07 c0 0f 48 73 14 48 00 78
			c0 07 c0 0f c8 71 13 48 00 78 40 06 c0 0f c8 70
			10 48 00 78 80 06 c0 0f 08 73 0e 48 00 78 c0 06
			c0 0f 08 71 0b 48 00 78 00 07 c0 0f 88 72 09 48
			00 78 40 07 c0 0f 48 72 06 48 00 78 80 07 c0 0f
			c8 73 04 48 00 78 c0 07 c0 0f 88 71 70 47 00 00
			61 00 00 20 62 00 00 20 5a 00 00 20 04 01 00 20
			03 48 00 88 03 49 08 40 01 49 08 80 70 47 00 00
			58 00 00 20 fe fe 00 00 10 b5 04 46 01 f0 b6 fb
			20 46 01 f0 d9 fb 80 b2 10 bd 70 47 70 47 00 00
			f8 b5 05 46 00 26 0d e0 6a 46 02 21 28 46 fe f7
			bf fe 00 28 00 d1 07 e0 00 f0 c4 f8 00 20 00 90
			70 1c c6 b2 03 2e ef db 00 bf 69 46 48 78 00 02
			09 78 08 43 04 b2 06 2d 02 d1 02 48 20 18 04 b2
			20 46 f8 bd 55 f5 ff ff fe b5 1e a0 00 68 02 90
			00 20 00 90 1f e0 02 aa 02 21 3e 20 fe f7 a5 fe
			06 46 00 2e 0f d1 00 f0 b7 f8 01 aa 04 21 40 20
			fe f7 8e fe 07 46 00 2f 00 d1 0f e0 00 f0 92 f8
			00 20 01 90 03 e0 00 f0 8d f8 00 20 01 90 00 98
			40 1c c0 b2 00 90 00 98 03 28 dc db 00 bf 68 46
			40 79 04 02 68 46 00 79 04 43 68 46 c0 79 05 02
			69 46 89 79 0d 43 ac 42 01 da 28 46 fe bd 20 46
			fc e7 00 00 71 00 00 00 10 b5 01 20 ff f7 8c ff
			6c 28 09 db 02 20 ff f7 87 ff 6c 28 04 db 03 20
			ff f7 82 ff 6c 28 05 da 08 48 00 78 40 1c 07 49
			08 70 02 e0 00 20 05 49 08 70 04 48 00 78 09 28
			01 dd 01 20 10 bd 00 20 fc e7 00 00 89 00 00 20
			10 b5 04 46 00 2c 02 d0 00 20 01 f0 97 f9 05 4a
			03 21 04 20 00 f0 0a fe 00 2c 02 d0 01 20 01 f0
			8d f9 10 bd 25 02 00 00 10 b5 04 46 00 2c 02 d0
			00 20 01 f0 83 f9 05 4a 03 21 0a 20 00 f0 f6 fd
			00 2c 02 d0 01 20 01 f0 79 f9 10 bd 25 02 00 00
			08 b5 08 e0 06 49 00 91 00 e0 00 bf 00 99 4a 1e
			00 92 00 29 f9 d1 01 46 40 1e 00 29 f2 d1 08 bd
			c9 29 00 00 08 b5 06 20 00 90 00 e0 00 bf 00 98
			41 1e 00 91 00 28 f9 d1 08 bd 10 b5 02 20 ff f7
			df ff 10 bd 08 b5 05 48 00 90 00 e0 00 bf 00 98
			41 1e 00 91 00 28 f9 d1 08 bd 00 00 62 0d 00 00
			08 b5 2c 20 00 90 00 e0 00 bf 00 98 41 1e 00 91
			00 28 f9 d1 08 bd 00 00 08 b5 05 48 00 90 00 e0
			00 bf 00 98 41 1e 00 91 00 28 f9 d1 08 bd 00 00
			37 02 00 00 10 b5 02 46 14 46 03 e0 ff f7 ec ff
			60 1e c4 b2 00 2c f9 dc 10 bd 70 47 8a b0 00 20
			09 90 00 26 00 27 08 90 07 90 06 90 05 90 04 90
			03 90 02 90 e1 20 40 01 fe 49 08 80 c3 20 80 00
			fd 49 08 80 fd 48 fe 49 08 60 fe 49 08 60 0a 20
			fd 49 08 70 f7 e2 01 f0 25 fe fc 48 00 68 00 28
			3a d1 58 20 01 f0 16 fc 05 46 f9 48 00 78 00 28
			2d d1 1f 2d 05 d1 00 f0 51 fb 01 20 f4 49 08 70
			18 e0 00 2d 03 d1 71 20 01 f0 70 fb 12 e0 0c 2d
			02 db 3f 20 01 90 0d e0 02 2d 07 db 0b 2d 05 dc
			68 1c 81 00 40 18 c0 b2 01 90 03 e0 01 2d 01 d1
			0f 20 01 90 e7 48 00 78 00 28 08 d1 e6 48 02 78
			e6 48 00 78 01 99 01 f0 1d fb e2 49 08 70 7d 20
			00 01 de 49 08 60 b3 e2 d9 48 00 68 00 28 70 d1
			0c 20 ff f7 95 fe 07 46 dd 48 87 42 05 dd ff f7
			61 ff 0c 20 ff f7 8c fe 07 46 3c 46 00 bf d4 48
			00 78 00 28 72 d1 d7 48 84 42 0a da 08 98 40 1c
			c0 b2 08 90 08 98 02 28 05 dd 77 20 01 f0 26 fb
			01 e0 00 20 08 90 ce 48 87 42 02 dd 75 20 01 f0
			1d fb cd 48 84 42 0a dd 04 98 40 1c c0 b2 04 90
			04 98 02 28 05 dd 74 20 01 f0 10 fb 01 e0 00 20
			04 90 c6 48 00 78 01 28 53 d1 c5 48 00 68 c5 49
			88 42 02 dd 05 20 07 90 25 e0 c1 48 00 68 c1 49
			49 1f 88 42 02 dd 04 20 07 90 1c e0 bc 48 00 68
			bc 49 14 39 88 42 02 dd 03 20 07 90 13 e0 b8 48
			00 68 b8 49 1e 39 88 42 02 dd 02 20 07 90 0a e0
			b3 48 00 68 b3 49 28 39 88 42 02 dd 01 20 07 90
			01 e0 00 20 07 90 b0 48 84 42 03 dd 00 20 06 90
			7b e0 c0 e0 ac 48 64 38 84 42 02 dd 01 20 06 90
			73 e0 a9 48 c8 38 84 42 02 dd 02 20 06 90 6c e0
			a6 48 84 42 03 dd 03 20 06 90 66 e0 a2 e0 a3 48
			64 38 84 42 02 dd 04 20 06 90 5e e0 05 20 06 90
			5b e0 9a 48 00 78 02 28 53 d1 99 48 00 68 99 49
			88 42 02 dd 05 20 07 90 25 e0 95 48 00 68 95 49
			49 1f 88 42 02 dd 04 20 07 90 1c e0 90 48 00 68
			90 49 14 39 88 42 02 dd 03 20 07 90 13 e0 8c 48
			00 68 8c 49 1e 39 88 42 02 dd 02 20 07 90 0a e0
			87 48 00 68 87 49 28 39 88 42 02 dd 01 20 07 90
			01 e0 00 20 07 90 84 48 96 30 84 42 02 dd 00 20
			06 90 22 e0 80 48 64 30 84 42 02 dd 01 20 06 90
			1b e0 e1 20 80 00 84 42 02 dd 02 20 06 90 14 e0
			7a 48 64 30 84 42 02 dd 03 20 06 90 0d e0 4b 20
			c0 00 84 42 02 dd 04 20 06 90 06 e0 05 20 06 90
			03 e0 00 20 07 90 05 20 06 90 06 99 07 98 40 18
			05 28 0a dd 03 98 40 1c c0 b2 03 90 03 98 05 28
			05 dd 5a 20 01 f0 4a fa 01 e0 00 20 03 90 68 48
			00 88 84 42 11 dd 66 48 00 88 66 49 88 42 0c dd
			65 48 00 78 00 28 05 d0 63 48 00 78 40 1e 62 49
			08 70 02 e0 55 20 01 f0 31 fa 59 48 00 68 59 49
			24 39 88 42 0f dd 5d 48 84 42 0c dd 4a 48 00 78
			40 1e 49 49 08 70 08 46 00 78 00 28 06 d1 55 20
			01 f0 1c fa 02 e0 0a 20 43 49 08 70 7d 20 c0 00
			3f 49 08 60 7c e1 52 48 00 68 00 28 70 d1 ff f7
			83 fd 06 46 4f 48 86 42 03 dc 7d 20 00 01 86 42
			0e da ff f7 27 fe ff f7 77 fd 06 46 49 48 86 42
			03 dc 7d 20 00 01 86 42 02 da 76 20 01 f0 f6 f9
			3b 48 06 60 32 48 00 78 00 28 52 d1 2a 48 00 88
			00 28 07 d1 31 48 00 78 3f 28 1e dd 3f 20 2f 49
			08 70 1a e0 24 48 00 88 ff 21 2d 31 88 42 07 da
			2a 48 00 78 3f 28 10 dd 3f 20 28 49 08 70 0c e0
			1d 48 00 88 ff 21 e1 31 88 42 06 da 23 48 00 78
			32 28 02 dd 32 20 21 49 08 70 2f 48 00 78 00 28
			19 d1 23 48 00 68 23 49 28 39 88 42 07 dd 1b 48
			00 78 3f 28 0f dd 3f 20 18 49 08 70 0b e0 1c 48
			00 68 26 49 88 42 06 dd 14 48 00 78 3f 28 02 dd
			3f 20 12 49 08 70 16 48 00 68 20 49 64 31 88 42
			40 dd 0e 48 00 78 3f 28 56 dd 3f 20 0b 49 37 e0
			8d e0 84 e0 68 00 00 20 6a 00 00 20 20 4e 00 00
			70 00 00 20 7c 00 00 20 91 00 00 20 74 00 00 20
			63 00 00 20 84 00 00 20 5f 00 00 20 86 00 00 20
			10 27 00 00 30 f8 ff ff 4c 1d 00 00 36 00 00 20
			38 00 00 20 8a 11 00 00 b6 03 00 00 8a 02 00 00
			8e 00 00 20 fc 08 00 00 90 00 00 20 e4 0c 00 00
			6c 00 00 20 88 13 00 00 87 00 00 20 68 10 00 00
			08 70 19 e0 68 48 00 68 21 21 c9 01 88 42 07 dd
			66 48 00 78 3f 28 0f dd 3f 20 64 49 08 70 0b e0
			61 48 00 68 62 49 88 42 06 dd 60 48 00 78 3f 28
			02 dd 3f 20 5d 49 08 70 5e 48 00 78 00 28 09 d1
			5d 48 02 78 5d 48 01 78 58 48 00 78 01 f0 0a f9
			58 49 08 70 5a 48 00 78 02 28 08 d1 52 48 00 68
			53 49 d2 31 88 42 02 dd 5a 20 01 f0 2f f9 4e 48
			00 68 54 49 88 42 02 dd 5a 20 01 f0 27 f9 4a 48
			00 68 50 49 0a 39 88 42 0a dd 09 98 40 1c c0 b2
			09 90 09 98 05 28 05 dd 5a 20 01 f0 17 f9 01 e0
			00 20 09 90 ff 20 f5 30 47 49 08 60 78 e0 47 48
			00 68 00 28 1f d1 06 20 ff f7 5a fc 04 46 44 48
			00 78 00 28 12 d1 00 2c 03 dd ff 20 f5 30 84 42
			0a dd 05 98 40 1c c0 b2 05 90 05 98 02 28 05 dd
			5c 20 01 f0 f3 f8 01 e0 00 20 05 90 ff 20 f5 30
			36 49 08 60 54 e0 37 48 00 68 00 28 1e d1 34 48
			00 78 00 28 0e d1 ff f7 97 fc 00 28 05 d0 00 20
			00 f0 b4 f8 01 20 2e 49 08 70 19 20 40 01 2d 49
			08 60 3d e0 02 98 00 28 04 d1 5d 20 01 f0 62 f9
			01 20 02 90 28 48 27 49 08 60 31 e0 27 48 00 78
			00 28 2d d1 26 48 00 88 00 28 06 d1 20 48 00 78
			00 28 02 d1 5a 20 01 f0 b9 f8 22 48 00 78 00 28
			02 d0 59 20 01 f0 b2 f8 1f 48 00 78 00 28 02 d0
			73 20 01 f0 ab f8 1d 48 00 78 00 28 02 d0 72 20
			01 f0 a4 f8 1a 48 00 78 00 28 03 d1 19 48 00 78
			01 28 02 dd 54 20 01 f0 99 f8 14 20 0f 49 08 70
			2f 20 ff f7 df fc 06 e5 38 00 00 20 86 00 00 20
			7c 10 00 00 84 00 00 20 5f 00 00 20 5e 00 00 20
			92 00 00 20 94 11 00 00 6c 00 00 20 7c 00 00 20
			63 00 00 20 80 00 00 20 10 27 00 00 78 00 00 20
			68 00 00 20 44 00 00 20 3f 00 00 20 3e 00 00 20
			3c 00 00 20 8d 00 00 20 30 e0 01 f0 03 fb 18 48
			00 68 00 28 0a d1 58 20 01 f0 f4 f8 00 28 01 d1
			01 f0 94 f8 13 48 12 49 08 60 1f e0 12 48 00 78
			00 28 1b d1 11 48 00 78 00 28 02 d0 73 20 01 f0
			4d f8 0f 48 00 78 00 28 02 d0 72 20 01 f0 46 f8
			0c 48 00 78 00 28 03 d1 0b 48 00 78 01 28 02 dd
			54 20 01 f0 3b f8 14 20 03 49 08 70 cd e7 00 00
			74 00 00 20 70 17 00 00 78 00 00 20 3f 00 00 20
			3e 00 00 20 3c 00 00 20 8d 00 00 20 00 28 08 d0
			09 49 c9 69 01 22 12 04 91 43 89 18 06 4a d1 61
			06 e0 05 49 c9 69 01 22 12 04 91 43 02 4a d1 61
			02 49 08 70 70 47 00 00 00 00 02 40 93 00 00 20
			03 48 c0 69 01 21 09 04 88 43 01 49 c8 61 70 47
			00 00 02 40 01 46 00 29 08 d0 01 29 15 d1 0c 48
			00 68 42 07 52 0f 0b 48 d0 40 70 47 08 48 00 68
			80 06 40 0f 00 28 01 d1 07 48 f6 e7 04 48 00 68
			80 06 42 0f 03 48 d0 40 ef e7 02 48 ed e7 00 00
			00 00 02 40 00 24 f4 00 00 12 7a 00 10 b5 05 20
			00 f0 98 f8 00 28 01 d0 01 20 10 bd 00 20 fc e7
			10 b5 09 20 00 f0 8e f8 00 28 01 d0 01 20 10 bd
			00 20 fc e7 03 48 c0 69 c0 03 c0 0f 01 21 48 40
			70 47 00 00 00 00 02 40 70 47 10 b5 01 20 80 07
			00 f0 90 fa c4 b2 64 06 64 0e 20 46 10 bd 00 00
			04 49 89 69 89 08 89 00 82 07 92 0f 11 43 01 4a
			91 61 70 47 00 00 01 40 05 49 89 69 0c 22 91 43
			82 00 0c 23 1a 40 11 43 01 4a 91 61 70 47 00 00
			00 00 01 40 70 b5 0b 48 85 6b 00 24 0e e0 01 20
			a0 40 28 40 00 28 08 d0 a0 00 07 49 08 58 00 28
			03 d0 a1 00 04 4a 50 58 80 47 64 1c 10 2c ee d3
			70 bd 00 00 00 00 01 40 b0 00 00 20 10 28 04 da
			01 21 81 40 03 4a 91 63 03 e0 00 21 c9 43 01 4a
			91 63 70 47 00 00 01 40 10 b5 02 46 10 2a 01 da
			10 48 00 e0 10 bd 00 bf 72 b6 00 bf 00 29 0a d1
			03 69 01 24 94 40 a3 43 03 61 83 68 01 24 94 40
			23 43 83 60 09 e0 83 68 01 24 94 40 23 43 83 60
			03 69 01 24 94 40 23 43 03 61 00 bf 62 b6 00 bf
			00 bf df e7 00 00 01 40 01 48 80 6b 70 47 00 00
			00 00 01 40 10 b5 01 46 10 29 01 da 0a 4a 01 e0
			00 20 10 bd 00 bf 72 b6 00 bf 10 68 01 24 8c 40
			20 40 00 28 01 d0 01 20 00 e0 00 20 03 46 00 bf
			62 b6 00 bf 18 46 ec e7 00 00 01 40 ff b5 81 b0
			04 46 15 46 1e 46 11 48 04 70 01 20 0f 49 48 70
			89 1c 02 a8 fe f7 ca f8 0c 48 85 71 c1 1d 30 46
			fe f7 c4 f8 09 48 c0 1d fe f7 b6 f8 00 90 07 48
			81 79 00 98 fe f7 a5 f8 04 48 00 f0 4f f8 07 46
			00 f0 9d f8 38 46 05 b0 f0 bd 00 00 15 01 00 20
			10 b5 00 bf 1f 48 00 68 40 08 40 00 1d 49 08 60
			08 46 00 68 04 21 88 43 1a 49 08 60 00 bf 00 20
			19 49 89 69 03 22 92 05 91 43 82 05 03 23 9b 05
			1a 40 11 43 14 4a 91 61 00 bf 00 bf 11 46 89 69
			9a 00 91 43 02 06 9b 00 1a 40 11 43 0e 4a 91 61
			00 bf 02 21 0c 20 00 f0 3b f9 02 21 0b 20 00 f0
			37 f9 00 21 0c 20 00 f0 69 f9 00 21 0b 20 00 f0
			65 f9 00 21 0c 20 ff f7 4f ff 00 21 0b 20 ff f7
			4b ff 10 bd 00 c0 00 40 00 00 01 40 70 b5 04 46
			fe f7 78 fc 21 78 49 06 08 0e fe f7 cb fb 01 28
			03 d1 fe f7 87 fc 01 20 70 bd 00 25 0d e0 a0 1c
			fe f7 4a f8 46 5d 30 46 fe f7 bc fb 01 28 03 d1
			fe f7 78 fc 01 20 ef e7 6d 1c 60 78 a8 42 ee d8
			fe f7 2a fc 21 78 49 00 49 1c c8 b2 fe f7 aa fb
			01 28 03 d1 fe f7 66 fc 01 20 dd e7 00 25 17 e0
			e0 1d fe f7 29 f8 06 46 a0 79 40 1e a8 42 01 d1
			01 20 00 e0 00 20 01 46 30 46 fe f7 0f fb e0 1d
			fe f7 1a f8 46 1c e1 1d 30 46 fe f7 1f f8 6d 1c
			a0 79 a8 42 e4 d8 fe f7 45 fc 00 20 bc e7 70 47
			70 b5 05 46 fe f7 26 fc 29 78 49 06 08 0e fe f7
			79 fb 01 28 03 d1 fe f7 35 fc 01 20 70 bd 00 24
			0d e0 a8 1c fd f7 f8 ff 06 5d 30 46 fe f7 6a fb
			01 28 03 d1 fe f7 26 fc 01 20 ef e7 64 1c 68 78
			a0 42 ee d8 00 24 0d e0 e8 1d fd f7 e5 ff 06 5d
			30 46 fe f7 57 fb 01 28 03 d1 fe f7 13 fc 01 20
			dc e7 64 1c a8 79 a0 42 ee d8 fe f7 0b fc 00 20
			d4 e7 00 00 37 b5 04 46 0b 48 04 70 01 20 0a 49
			48 70 89 1c 01 a8 fd f7 d1 ff 02 20 06 49 88 71
			c9 1d 02 a8 fd f7 ca ff 03 48 ff f7 b1 ff 05 46
			ff f7 ad ff 28 46 3e bd 15 01 00 20 f8 b5 05 46
			0e 46 17 46 10 2d 01 da 36 4c 00 e0 f8 bd 00 21
			28 46 ff f7 91 fe 00 2e 06 d0 01 2e 0f d0 02 2e
			18 d0 03 2e 2c d1 20 e0 a0 6a 01 21 a9 40 88 43
			a0 62 20 6b 01 21 a9 40 88 43 20 63 21 e0 a0 6a
			01 21 a9 40 08 43 a0 62 20 6b 01 21 a9 40 88 43
			20 63 16 e0 a0 6a 01 21 a9 40 88 43 a0 62 20 6b
			01 21 a9 40 08 43 20 63 0b e0 a0 6a 01 21 a9 40
			08 43 a0 62 20 6b 01 21 a9 40 08 43 20 63 00 e0
			c4 e7 00 bf a8 00 18 49 0f 50 e1 6b 01 20 a8 40
			81 43 e1 63 20 6a 01 21 a9 40 08 43 20 62 11 20
			00 28 0c db 11 49 09 68 c3 06 db 0e 01 22 9a 40
			11 40 00 29 01 d0 01 21 02 e0 00 21 00 e0 00 21
			00 29 0d d1 11 20 00 28 05 db c2 06 d2 0e 01 21
			91 40 06 4a 11 60 00 bf 00 21 11 20 fe f7 06 f9
			00 bf 93 e7 00 00 01 40 b0 00 00 20 00 e1 00 e0
			10 b5 02 46 10 2a 01 da 17 48 00 e0 10 bd 00 29
			04 d0 01 29 0d d0 02 29 21 d1 15 e0 43 6c 01 24
			94 40 23 43 43 64 83 6c 01 24 94 40 a3 43 83 64
			16 e0 43 6c 01 24 94 40 a3 43 43 64 83 6c 01 24
			94 40 23 43 83 64 0b e0 43 6c 01 24 94 40 a3 43
			43 64 83 6c 01 24 94 40 a3 43 83 64 00 e0 00 bf
			00 bf 00 bf d2 e7 00 00 00 00 01 40 10 b5 02 46
			10 2a 01 da 0b 48 00 e0 10 bd 00 bf 72 b6 00 bf
			01 29 05 d1 43 68 01 24 94 40 23 43 43 60 04 e0
			44 68 01 23 93 40 9c 43 44 60 00 bf 62 b6 00 bf
			00 bf e9 e7 00 00 01 40 10 b5 01 20 81 07 c8 60
			01 48 00 68 80 47 10 bd 04 00 00 20 10 b5 01 20
			02 49 c8 60 02 48 00 68 80 47 10 bd 00 10 00 40
			08 00 00 20 01 46 48 68 70 47 01 46 08 68 c0 07
			c0 0f 70 47 f8 b5 04 46 0e 46 15 46 01 20 ff f7
			19 fd 7d 21 c9 00 00 90 fd f7 82 fe 70 43 07 46
			a7 60 67 60 00 20 c0 43 e0 60 20 68 08 21 88 43
			08 30 20 60 c8 06 84 42 09 d1 0a 48 05 60 02 21
			08 20 fe f7 a7 f8 08 20 fe f7 5c f8 08 e0 06 48
			05 60 02 21 09 20 fe f7 9d f8 09 20 fe f7 52 f8
			f8 bd 00 00 04 00 00 20 08 00 00 20 01 68 49 08
			49 00 49 1c 01 60 70 47 10 b5 ff f7 e9 fd 10 bd
			0d 48 41 68 0d 4b c9 01 0e d5 41 68 c9 03 0b d4
			00 21 c9 43 41 60 41 6f 82 15 91 43 41 67 08 4a
			00 21 51 70 d1 60 19 70 19 78 04 4a 89 00 08 32
			52 58 02 49 10 47 00 00 00 c0 00 40 0c 00 00 20
			f0 00 00 20 01 21 0d 4a 0b 48 89 04 11 60 bf f3
			4f 8f bf f3 6f 8f 51 17 41 60 41 6f 82 15 91 43
			41 67 00 21 81 60 01 68 49 08 49 00 01 60 01 68
			04 22 91 43 01 60 70 47 00 c0 00 40 80 e1 00 e0
			0c 48 0d 49 89 6b 00 29 08 d0 0b 49 89 6b 3f 22
			12 02 11 40 09 0a 09 4a 11 61 0a e0 08 49 41 60
			08 49 01 60 81 68 3f 22 12 02 11 40 09 0a 03 4a
			11 61 70 47 00 30 00 40 00 00 02 40 00 e0 00 40
			02 00 00 80 01 4f 4c 46 e2 48 c0 69 01 21 09 04
			88 43 e0 49 c8 61 08 46 c0 69 10 21 88 43 dd 49
			c8 61 ff f7 cd ff 00 f0 03 fa fe f7 95 fa 00 f0
			0d fe 00 f0 fe f9 ff f7 7f ff 00 20 ff f7 54 f8
			01 20 00 f0 db f9 53 20 00 f0 7c fd 05 46 2d 07
			2d 0f 00 2d 01 d1 0a 24 11 e0 01 2d 01 d1 3c 24
			0d e0 02 2d 01 d1 82 24 09 e0 03 2d 01 d1 aa 24
			05 e0 04 2d 02 d1 ff 24 05 34 00 e0 0a 24 32 2c
			0b db 78 2c 09 da c4 48 c4 49 08 60 04 20 c4 49
			08 70 02 20 c3 49 08 70 34 e0 78 2c 0b db a0 2c
			09 da c1 48 bd 49 08 60 06 20 bd 49 08 70 01 20
			be 49 08 70 26 e0 a0 2c 0b db fa 2c 09 da bc 48
			b6 49 08 60 06 20 b6 49 08 70 01 20 b7 49 08 70
			18 e0 fa 2c 0d db ff 20 af 30 84 42 09 da b5 48
			ae 49 08 60 06 20 ae 49 08 70 02 20 af 49 08 70
			08 e0 b1 48 a9 49 08 60 04 20 a9 49 08 70 02 20
			a8 49 08 70 a6 49 08 78 c1 0f 09 18 49 10 ab 4a
			11 70 10 46 00 78 08 21 08 40 c0 10 a8 49 08 70
			10 46 00 78 04 21 08 40 80 10 a6 49 08 70 10 46
			00 78 02 21 08 40 40 10 a3 49 08 70 10 46 00 78
			c0 07 c0 0f a1 49 08 70 00 f0 46 fc 00 f0 5c fc
			00 f0 6c fb 00 f0 42 fb 00 20 fe f7 b1 ff 00 bf
			ff f7 2b f8 00 f0 60 fc 00 28 f9 d0 00 f0 65 fe
			15 e0 00 f0 67 fe 96 48 00 78 00 28 01 d0 00 f0
			fd fb 94 48 00 78 01 28 04 d1 93 48 00 78 01 28
			00 d1 05 e0 91 48 00 78 00 28 00 d1 00 e0 e8 e7
			00 bf 01 20 8e 49 08 70 fe f7 ff fe 52 20 00 f0
			41 fc 05 46 01 20 8b 49 08 70 00 2d 01 d1 00 f0
			dd fb 00 f0 3f fe 5e 20 00 f0 34 fc 05 46 02 2d
			01 d0 00 f0 d3 fb 00 f0 35 fe fe f7 b6 ff 00 f0
			31 fe 81 48 00 78 00 f0 25 fc 05 46 02 2d 01 d0
			00 f0 c4 fb 00 f0 26 fe 00 f0 24 fe 7a 48 00 78
			00 28 03 d0 fe f7 f8 fe 78 49 08 60 fe f7 9d ff
			75 48 00 78 00 28 03 d0 2c 20 fe f7 c9 fe c6 b2
			55 2e 25 dd fa 2c 05 db 14 20 71 49 08 70 71 49
			08 70 8a e0 a0 2c 05 db 0f 20 6d 49 08 70 6d 49
			08 70 82 e0 78 2c 05 db 0f 20 69 49 08 70 69 49
			08 70 7a e0 32 2c 05 db 0a 20 65 49 08 70 65 49
			08 70 72 e0 0a 20 62 49 08 70 62 49 08 70 6c e0
			4b 2e 25 dd fa 2c 05 db 1e 20 5d 49 08 70 5d 49
			08 70 62 e0 a0 2c 05 db 19 20 59 49 08 70 59 49
			08 70 5a e0 78 2c 05 db 14 20 55 49 08 70 55 49
			08 70 52 e0 32 2c 05 db 0a 20 51 49 08 70 51 49
			08 70 4a e0 0a 20 4e 49 08 70 4e 49 08 70 44 e0
			32 2e 25 dd fa 2c 05 db 28 20 49 49 08 70 49 49
			08 70 3a e0 a0 2c 05 db 28 20 45 49 08 70 45 49
			08 70 32 e0 78 2c 05 db 1c 20 41 49 08 70 41 49
			08 70 2a e0 32 2c 05 db 0f 20 3d 49 08 70 3d 49
			08 70 22 e0 0a 20 3a 49 08 70 3a 49 08 70 1c e0
			a0 2c 05 db 3f 20 36 49 08 70 36 49 08 70 14 e0
			78 2c 05 db 32 20 32 49 08 70 32 49 08 70 0c e0
			32 2c 05 db 18 20 2e 49 08 70 2e 49 08 70 04 e0
			14 20 2b 49 08 70 2b 49 08 70 fe f7 fe fe ff f7
			1b fb 58 20 00 f0 6e fb 01 20 27 49 08 70 1f 48
			00 78 00 28 01 d1 ff f7 67 fa 0c e0 00 f0 6a fd
			17 48 00 78 00 28 03 d1 1a 48 00 78 01 28 02 dd
			54 20 00 f0 c3 fa ff f7 f5 fa 01 28 ee d0 fe f7
			15 ff 00 00 00 00 02 40 dc 33 00 00 2c 00 00 20
			30 00 00 20 92 00 00 20 f8 33 00 00 36 00 00 20
			22 34 00 00 4c 34 00 00 c0 33 00 00 31 00 00 20
			32 00 00 20 33 00 00 20 34 00 00 20 35 00 00 20
			3c 00 00 20 5c 00 00 20 56 00 00 20 8b 00 00 20
			5d 00 00 20 8d 00 00 20 52 00 00 20 38 00 00 20
			85 00 00 20 86 00 00 20 43 00 00 20 00 28 09 d0
			0a 49 09 78 00 29 05 d1 00 bf 62 b6 00 bf 07 49
			08 70 0a e0 00 28 08 d1 04 49 09 78 00 29 04 d0
			00 bf 72 b6 00 bf 01 49 08 70 70 47 a8 00 00 20
			70 47 10 b5 ff f7 5c fa 00 f0 16 fa 00 f0 ec f9
			00 f0 f4 f9 00 f0 ca f9 fe f7 b0 fd 10 bd 00 00
			70 b5 06 46 1c 4d 1d 4c 01 20 ff f7 a1 fa 06 2e
			0b d1 e0 69 01 21 49 04 88 43 40 18 e0 61 e0 69
			89 00 88 43 40 18 e0 61 16 e0 69 68 09 01 89 0e
			10 22 11 43 89 05 3f 22 92 05 11 40 08 46 69 68
			91 43 01 43 69 60 e0 69 01 21 49 04 88 43 e0 61
			e0 69 89 00 88 43 e0 61 69 68 89 05 89 0e 10 22
			11 43 09 01 3f 22 12 01 11 40 08 46 69 68 91 43
			01 43 69 60 70 bd 00 00 00 70 00 40 00 00 02 40
			70 b5 06 46 17 4c 18 4d 01 20 ff f7 6d fa 07 2e
			06 d1 e8 69 01 21 89 04 88 43 40 18 e8 61 12 e0
			61 68 09 01 89 0e 20 22 11 43 89 05 3f 22 92 05
			11 40 08 46 61 68 91 43 01 43 61 60 e8 69 01 21
			89 04 88 43 e8 61 61 68 89 05 89 0e 20 22 11 43
			09 01 3f 22 12 01 11 40 08 46 61 68 91 43 01 43
			61 60 70 bd 00 70 00 40 00 00 02 40 70 b5 02 46
			31 49 32 48 13 00 fd f7 2f fd 08 05 06 07 08 09
			0a 1a 34 4a 00 bf 00 bf 00 bf 00 bf 00 bf 4c 68
			a4 05 a4 0e 01 25 95 40 ac 43 24 01 3f 25 2d 01
			2c 40 23 46 4c 68 ac 43 1c 43 4c 60 42 e0 4c 68
			a4 05 a4 0e 95 1e 01 26 ae 40 b4 43 24 01 3f 25
			2d 01 2c 40 23 46 4c 68 ac 43 1c 43 4c 60 c3 69
			01 24 64 04 a3 43 c3 61 c3 69 a4 00 a3 43 c3 61
			28 e0 4c 68 a4 05 a4 0e 95 1e 01 26 ae 40 b4 43
			24 01 3f 25 2d 01 2c 40 23 46 4c 68 ac 43 1c 43
			4c 60 c3 69 01 24 a4 04 a3 43 c3 61 12 e0 4b 68
			3f 24 24 01 a3 43 4b 60 c3 69 01 24 64 04 a3 43
			c3 61 c3 69 a4 00 a3 43 c3 61 c3 69 64 10 a3 43
			c3 61 00 bf 00 bf 70 bd 00 70 00 40 00 00 02 40
			70 b5 05 46 3c 4c 2b 00 fd f7 c6 fc 09 1a 2a 49
			4a 69 6e 6a 6f 06 73 00 60 68 3f 21 89 05 88 43
			1f 21 c9 05 40 18 60 60 60 68 3f 21 09 01 08 43
			60 60 01 20 ff f7 ac f9 01 20 ff f7 b5 f9 59 e0
			61 68 89 05 89 0e 01 22 aa 40 11 43 09 01 3f 22
			12 01 11 40 08 46 61 68 91 43 01 43 61 60 49 e0
			61 68 09 01 89 0e 01 22 aa 40 11 43 89 05 3f 22
			92 05 11 40 08 46 61 68 91 43 01 43 61 60 61 68
			89 05 89 0e 01 22 aa 40 11 43 09 01 3f 22 12 01
			11 40 08 46 61 68 91 43 01 43 61 60 2a e0 00 bf
			61 68 09 01 89 0e 01 22 aa 40 11 43 89 05 3f 22
			92 05 11 40 08 46 61 68 91 43 01 43 61 60 61 68
			89 05 89 0e 01 22 aa 40 11 43 09 01 3f 22 12 01
			11 40 08 46 61 68 91 43 01 43 61 60 0a e0 00 bf
			28 46 ff f7 ad fe 05 e0 00 bf 28 46 ff f7 e8 fe
			00 e0 00 bf 00 bf 70 bd 00 70 00 40 07 48 08 49
			09 78 01 29 00 d1 70 47 01 21 05 4a 11 70 05 49
			41 60 00 21 c9 43 c1 60 00 bf f4 e7 00 70 00 40
			00 00 00 20 01 0c 00 00 06 49 ca 68 ca 60 40 23
			13 40 00 2b 04 d0 00 20 00 e0 40 1c 05 28 fc d9
			70 47 00 00 00 70 00 40 70 b5 04 46 1e 4d 08 2c
			01 db 00 20 70 bd 20 46 ff f7 52 ff 00 bf 1a 48
			00 68 40 08 40 00 40 1c 17 49 08 60 00 bf 64 23
			00 22 04 21 28 46 00 f0 3f fb 00 28 22 d0 20 46
			ff f7 d4 fe 06 2c 09 d1 a0 1e 81 00 28 46 10 30
			40 58 86 05 b6 0d 0a 20 46 43 11 e0 07 2c 09 d1
			a0 1e 81 00 28 46 10 30 40 58 86 05 b6 0d 06 20
			46 43 05 e0 a1 00 28 46 10 30 40 58 86 05 b6 0d
			30 46 c7 e7 00 20 c5 e7 00 70 00 40 10 b5 00 21
			04 20 ff f7 21 f9 10 bd 10 b5 00 21 04 20 ff f7
			2d fb 01 21 04 20 ff f7 17 f9 10 bd 10 b5 04 46
			00 2c 04 d0 01 21 04 20 ff f7 20 fb 03 e0 00 21
			04 20 ff f7 1b fb 10 bd 10 b5 00 21 0a 20 ff f7
			df fa 00 21 0a 20 ff f7 ff f8 10 bd 10 b5 00 21
			05 20 ff f7 f9 f8 10 bd 10 b5 00 21 05 20 ff f7
			05 fb 01 21 05 20 ff f7 ef f8 10 bd 10 b5 04 46
			00 2c 04 d0 01 21 05 20 ff f7 f8 fa 03 e0 00 21
			05 20 ff f7 f3 fa 10 bd 10 b5 00 21 09 20 ff f7
			db f8 10 bd 10 b5 00 21 09 20 ff f7 e7 fa 01 21
			09 20 ff f7 d1 f8 10 bd 10 b5 04 46 00 2c 04 d0
			01 21 09 20 ff f7 da fa 03 e0 00 21 09 20 ff f7
			d5 fa 10 bd 30 b5 03 46 10 48 04 78 10 48 00 78
			98 42 01 dd 0e 48 03 70 0e 48 01 70 0e 48 02 70
			91 42 00 da 0a 46 0a 48 00 78 90 42 02 dd 07 48
			02 70 03 e0 06 48 00 78 04 4d 28 70 03 48 00 78
			84 42 01 d0 05 20 30 bd 00 20 fc e7 85 00 00 20
			86 00 00 20 5e 00 00 20 5f 00 00 20 02 48 01 69
			02 69 0a 43 02 61 70 47 00 a0 00 40 10 b5 04 46
			00 f0 98 fa 00 20 fe f7 d1 ff ff f7 87 ff 20 46
			00 f0 88 f8 00 f0 2a f8 10 bd 00 00 70 b5 04 46
			00 20 fe f7 e7 ff 60 43 05 46 00 bf 0b 48 0c 49
			08 60 00 bf 0b 48 05 60 45 60 03 20 09 49 88 60
			09 48 00 68 40 21 88 43 40 30 07 49 08 60 00 bf
			00 20 03 49 08 60 00 bf 70 bd 00 00 51 e5 cc 1a
			00 8c 00 40 00 80 00 40 00 00 02 40 00 bf 00 bf
			00 bf 00 bf 00 bf bf f3 4f 8f 00 bf 00 bf 00 bf
			06 48 07 49 c8 60 00 bf 00 bf 00 bf bf f3 4f 8f
			00 bf 00 bf 00 bf 00 bf 00 bf fd e7 04 00 fa 05
			00 ed 00 e0 10 b5 07 48 00 78 02 28 09 d0 05 48
			00 78 01 28 03 d1 02 20 02 49 08 70 01 e0 ff f7
			d5 ff 10 bd 8d 00 00 20 10 b5 00 24 ff f7 04 ff
			00 bf 0d e0 00 20 ff f7 09 ff 01 20 fe f7 da fb
			01 20 ff f7 03 ff 03 20 fe f7 d4 fb 60 1c c4 b2
			1e 2c ef db 10 bd 00 00 10 b5 03 4a 01 21 88 07
			ff f7 58 fa 10 bd 00 00 e9 03 00 00 10 b5 01 20
			80 07 ff f7 83 fa 10 bd 10 b5 01 20 80 07 ff f7
			44 fa 10 bd fe b5 05 46 00 27 00 f0 03 fa 01 95
			00 20 3e 49 08 70 ff f7 15 ff fe f7 91 fb 00 20
			ff f7 1a ff fe f7 79 fb 01 20 ff f7 15 ff 00 24
			1f e0 37 48 00 78 00 28 03 d0 58 2d 01 d1 ff f7
			dd fe 00 f0 e7 f9 00 bf 30 48 00 78 00 28 fb d0
			00 f0 e0 f9 06 20 01 1b 01 98 08 41 c0 07 c0 0f
			00 90 00 98 ff f7 f8 fe 00 20 28 49 08 70 60 1c
			c4 b2 07 2c dd db 00 f0 cd f9 00 24 28 e0 24 48
			00 78 00 28 03 d0 58 2d 01 d1 ff f7 b7 fe 00 f0
			c1 f9 00 bf 1d 48 00 78 00 28 fb d0 00 f0 ba f9
			00 2c 03 d1 ff f7 c8 fe fe f7 4a fb 00 20 17 49
			08 70 fe f7 3d ff 06 46 06 2c 07 d0 00 2c 05 d0
			05 20 01 1b 30 46 88 40 38 43 c7 b2 60 1c c4 b2
			07 2c d4 db 00 f0 9e f9 00 bf 0c 48 00 78 00 28
			fb d0 00 f0 97 f9 ff f7 ad fe fe f7 29 fb 00 20
			ff f7 b2 fe 00 20 05 49 08 70 fe f7 0e fb fe f7
			0c fb 00 f0 87 f9 38 46 fe bd 00 00 3d 00 00 20
			3c 00 00 20 fe b5 05 46 00 27 00 f0 7b f9 01 95
			00 20 3c 49 08 70 ff f7 8d fe fe f7 09 fb 00 20
			ff f7 92 fe fe f7 f1 fa 01 20 ff f7 8d fe 00 24
			1f e0 35 48 00 78 00 28 03 d0 58 2d 01 d1 ff f7
			55 fe 00 f0 5f f9 00 bf 2e 48 00 78 00 28 fb d0
			00 f0 58 f9 06 20 01 1b 01 98 08 41 c0 07 c0 0f
			00 90 00 98 ff f7 70 fe 00 20 26 49 08 70 60 1c
			c4 b2 07 2c dd db 00 f0 45 f9 00 24 24 e0 22 48
			00 78 00 28 03 d0 58 2d 01 d1 ff f7 2f fe 00 f0
			39 f9 00 bf 1b 48 00 78 00 28 fb d0 00 f0 32 f9
			00 2c 03 d1 ff f7 40 fe fe f7 c2 fa 00 20 15 49
			08 70 fe f7 b5 fe 06 46 06 20 01 1b 30 46 88 40
			38 43 c7 b2 60 1c c4 b2 07 2c d8 db 00 f0 1a f9
			00 bf 0c 48 00 78 00 28 fb d0 00 f0 13 f9 ff f7
			29 fe fe f7 a5 fa 00 20 ff f7 2e fe 00 20 05 49
			08 70 fe f7 8a fa fe f7 88 fa 00 f0 03 f9 38 46
			fe bd 00 00 3d 00 00 20 3c 00 00 20 00 20 2e 49
			08 70 2e 49 08 70 2e 49 08 70 2e 49 08 70 2e 49
			08 70 2e 49 08 70 2e 49 08 70 2e 49 08 70 2e 49
			08 70 01 20 2d 49 08 70 00 20 48 70 88 70 2c 49
			08 70 2c 49 08 70 2c 49 08 70 2c 49 08 70 03 20
			2b 49 08 70 00 20 2b 49 08 70 2b 49 08 70 2b 49
			08 70 2b 49 08 80 40 1e 2a 49 08 80 00 20 2a 49
			08 70 2a 49 08 70 3f 20 29 49 08 70 29 49 08 70
			00 20 29 49 08 70 29 49 08 70 29 49 08 70 3f 20
			28 49 08 70 28 49 08 70 01 20 28 49 08 70 28 49
			08 70 00 20 27 49 08 70 27 49 08 70 02 20 27 49
			08 70 03 20 26 49 08 70 00 20 26 49 08 70 26 49
			08 70 26 49 08 70 70 47 3c 00 00 20 43 00 00 20
			44 00 00 20 3e 00 00 20 3f 00 00 20 40 00 00 20
			41 00 00 20 42 00 00 20 4d 00 00 20 04 01 00 20
			4e 00 00 20 50 00 00 20 51 00 00 20 52 00 00 20
			53 00 00 20 54 00 00 20 55 00 00 20 56 00 00 20
			58 00 00 20 5a 00 00 20 5c 00 00 20 5d 00 00 20
			5e 00 00 20 5f 00 00 20 60 00 00 20 63 00 00 20
			84 00 00 20 85 00 00 20 86 00 00 20 87 00 00 20
			88 00 00 20 89 00 00 20 8a 00 00 20 8b 00 00 20
			8c 00 00 20 8d 00 00 20 92 00 00 20 36 00 00 20
			f8 b5 00 bf 00 bf 00 bf 00 bf 07 20 fe f7 f4 f8
			40 00 ff 30 ff 30 02 30 7d 21 c9 00 48 43 07 46
			10 49 fc f7 23 ff 04 46 06 20 fe f7 e5 f8 40 00
			ff 30 ff 30 02 30 7d 21 c9 00 48 43 07 46 09 49
			fc f7 14 ff 05 46 64 1b 64 26 c8 20 00 90 b4 42
			01 da 00 20 f8 bd 00 98 84 42 01 dd 02 20 f9 e7
			01 20 f7 e7 ff 03 00 00 78 b5 04 46 0d 46 1e 46
			7d 20 c0 00 70 43 00 90 00 bf 20 68 28 40 90 42
			01 d1 01 20 78 bd 00 98 40 1e 00 90 fe f7 82 f9
			00 98 00 28 f1 d1 00 bf f4 e7 10 b5 01 20 ff f7
			75 fd 10 bd 00 bf 07 48 07 49 08 60 00 bf 00 bf
			01 20 06 49 c8 60 00 bf 00 bf 00 20 02 49 08 60
			00 bf 70 47 51 e5 cc 1a 00 8c 00 40 00 80 00 40
			00 00 00 01 01 01 00 01 00 00 01 01 01 00 00 00
			00 01 00 01 00 01 01 00 00 01 01 00 00 00 01 00
			01 00 00 01 00 00 01 01 01 00 00 00 00 01 00 01
			00 01 01 00 00 01 01 00 00 01 00 01 00 00 00 01
			00 00 01 01 01 00 00 00 01 01 01 00 00 01 01 00
			01 00 00 01 00 00 00 01 00 01 00 01 01 00 01 01
			00 00 00 01 00 01 00 00 00 01 00 01 00 00 01 00
			00 00 01 01 01 01 00 01 01 00 01 00 00 01 00 00
			00 01 00 01 00 01 01 00 01 01 00 00 00 01 00 01
			00 00 00 01 00 01 00 00 01 00 00 00 01 01 01 01
			00 01 01 00 01 00 00 01 00 00 00 01 01 00 00 01
			01 00 01 01 00 00 00 00 98 34 00 00 00 00 00 20
			b0 00 00 00 1c 06 00 00 48 35 00 00 b0 00 00 20
			70 04 00 00 2c 06 00 00 00 00 00 00 00 00 00 00
			00 00 00 00 00 00 00 00 00 00 00 00 45 07 00 00
			fd 06 00 00 3d 06 00 00 7d 06 00 00 ad 06 00 00
			6d 07 00 00 00 00 00 00 00 00 00 00 00 00 00 00
			00 00 00 00 00 00 00 00 00 00 00 00 00 00 00 00
			00 00 00 00 00 00 00 00 00 00 00 00 00 00 00 00
			00 00 00 00 00 00 00 00 00 00 00 00 00 00 00 00
			00 00 00 00 00 00 00 00 00 00 00 00 00 00 00 00
			00 00 00 00 00 00 00 00 00 00 00 00 00 00 00 00
			00 00 00 00 00 00 00 00 00 00 00 00 00 00 00 00
			00 00 00 00 00 00 00 00 00 00 00 00 00 02 00 01
			07 01 04 00 15 34 55 34
		];

		qcom,vooc-max-input-volt-support = <10000>;     //10V
		qcom,vooc-max-input-current-support = <6500>;   //6A
		vooc_charge_strategy_30w {
			strategy_1 {
				capacity_range = <0 75>;
				temp_range = <120 160>;
				input_current = <4000 4450 0
												3000 4470 0
												2000 4480 0>;
				};
			strategy_2 {
				capacity_range = <0 75>;
				temp_range = <160 410>;
				input_current = <6000 4200 900
												5000 4200 0
												4500 4450 0
												4000 4450 0
												3000 4470 0
												2000 4480 0>;
			};
			strategy_3 {
				capacity_range = <0 75>;
				temp_range = <410 420>;
				input_current = <4000 4470 0
												2000 4480 0>;
			};
			strategy_4 {
				capacity_range = <0 75>;
				temp_range = <420 425>;
				input_current = <4000 4480 0>;
			};
			strategy_5 {
				capacity_range = <0 75>;
				temp_range = <425 435>;
				input_current = <3000 4480 0>;
			};
		};

		vooc_charge_strategy_65w {
			strategy_1 {
				capacity_range = <0 50>;
				temp_range = <120 160>;
				input_current = <6000 4200 0
												4000 4454 0
												2000 4494 0
												1500 4500 0>;
			};
			strategy_2 {
				capacity_range = <0 50>;
				temp_range = <160 370>;
				input_current = <6500 4200 0
												6000 4250 300
												5500 4300 400
												4500 4454 780
												3500 4454 0
												2000 4494 0
												1500 4500 0>;
			};
			strategy_3 {
				capacity_range = <0 90>;
				temp_range = <370 430>;
				input_current = <6500 4200 0
												6000 4250 300
												5500 4300 400
												4500 4454 780
												3500 4454 0
												2000 4494 0
												1600 4500 0>;
			};
		};
	};
};

&i2c11 {
	status = "okay";
	clock-frequency = <100000>;

	charge_pump-divider@68 {
		status = "okay";
		compatible = "oplus,charge_pump-divider";
		reg = <0x68 0>;
		oplus,charge_pump-hwid-gpio = <&pio 185 0>;
		pinctrl-names = "charge_pump_hwid_active", "charge_pump_hwid_sleep", "charge_pump_hwid_default";
		pinctrl-0 = <&charge_pump_hwid_active>;
		pinctrl-1 = <&charge_pump_hwid_sleep>;
		pinctrl-2 = <&charge_pump_hwid_default>;
	};

	mp2650-charger@5c {
		status = "okay";
		compatible = "oplus,mp2650-charger";
		reg = <0x5c 0>;

		qcom,mps_otg_en-gpio = <&pio 129 0x00>;
		pinctrl-names = "mps_otg_en_active", "mps_otg_en_sleep", "mps_otg_en_default";
		pinctrl-0 = <&mps_otg_en_active>;
		pinctrl-1 = <&mps_otg_en_sleep>;
		pinctrl-2 = <&mps_otg_en_default>;
	};
};

&pio {
	charger_pins_default: eint0default {
	};

	charger_pins_eint_output0: charger_gpio_as_output_low {
		pins_cmd_dat {
			pinmux = <PINMUX_GPIO192__FUNC_GPIO192>;
			slew-rate = <1>;
			output-low;
		};
	};

	charger_pins_eint_output1: charger_gpio_as_output_high {
		pins_cmd_dat {
			pinmux = <PINMUX_GPIO192__FUNC_GPIO192>;
			slew-rate = <1>;
			output-high;
		};
	};

	ship_sleep_gpio: ship_sleep {
		pins_cmd_dat {
			pinmux = <PINMUX_GPIO27__FUNC_GPIO27>;
			slew-rate = <1>;
			output-low;
		};
	};

	ship_active_gpio: ship_active {
		pins_cmd_dat {
			pinmux = <PINMUX_GPIO27__FUNC_GPIO27>;
			slew-rate = <1>;
			output-high;
		};
	};

	dischg_enable: dischg_enable {
		pins_cmd_dat {
			pinmux = <PINMUX_GPIO51__FUNC_GPIO51>;
			slew-rate = <1>;
			bias-pull-up;
			output-high;
		};
	};

	dischg_disable: dischg_disable {
		pins_cmd_dat {
			pinmux = <PINMUX_GPIO51__FUNC_GPIO51>;
			slew-rate = <1>;
			bias-pull-down;
			output-low;
		};
	};

	vooc_asic_id_active: vooc_asic_id_active {
		pins_cmd_dat {
			pinmux = <PINMUX_GPIO187__FUNC_GPIO187>;
			input-enable;
			slew-rate = <0>;
			bias-pull-up;
		};
	};

	vooc_asic_id_sleep: vooc_asic_id_sleep {
		pins_cmd_dat {
			pinmux = <PINMUX_GPIO187__FUNC_GPIO187>;
			input-enable;
			slew-rate = <0>;
			bias-pull-down;
		};
	};

	ccdetect_active: ccdetect_active {
		pins_cmd_dat {
			pinmux = <PINMUX_GPIO5__FUNC_GPIO5>;
			input-enable;
			slew-rate = <0>;
			bias-disable;
		};
	};

	ccdetect_sleep: ccdetect_sleep {
		pins_cmd_dat {
			pinmux = <PINMUX_GPIO5__FUNC_GPIO5>;
			input-enable;
			slew-rate = <0>;
			bias-disable;
		};
	};

	chgvin_enable: chgvin_enable {
		pins_cmd_dat {
			pinmux = <PINMUX_GPIO30__FUNC_GPIO30>;
			slew-rate = <1>;//0:input direction 1:output direction
			bias-pull-up;
			output-low;
		};
	};

	chgvin_disable: chgvin_disable {
		pins_cmd_dat {
			pinmux = <PINMUX_GPIO30__FUNC_GPIO30>;
			slew-rate = <1>;
			bias-pull-down;
			output-high;
		};
	};

	pmic_chgfunc_enable: pmic_chgfunc_enable {
		pins_cmd_dat {
			pinmux = <PINMUX_GPIO26__FUNC_GPIO26>;
			slew-rate = <1>;//0:input direction 1:output direction
			bias-pull-up;
			output-low;
		};
	};

	pmic_chgfunc_disable: pmic_chgfunc_disable {
		pins_cmd_dat {
			pinmux = <PINMUX_GPIO26__FUNC_GPIO26>;
			slew-rate = <1>;
			bias-pull-down;
			output-high;
		};
	};

	charging_switch1_active: charging_switch1_active {
		pins_cmd_dat {
			pinmux = <PINMUX_GPIO191__FUNC_GPIO191>;
			slew-rate = <1>;
			output-high;
		};
	};

	charging_switch1_sleep: charging_switch1_sleep {
		pins_cmd_dat {
			pinmux = <PINMUX_GPIO191__FUNC_GPIO191>;
			slew-rate = <1>;
			output-low;
		};
	};

	charging_switch1_ctr1_active: charging_switch1_ctr1_active {
		pins_cmd_dat {
			pinmux = <PINMUX_GPIO163__FUNC_GPIO163>;
			slew-rate = <1>;
			bias-pull-up;
		};
	};

	charging_switch1_ctr1_sleep: charging_switch1_ctr1_sleep {
		pins_cmd_dat {
			pinmux = <PINMUX_GPIO163__FUNC_GPIO163>;
			slew-rate = <1>;
			output-low;
		};
	};

	charging_clock_active: charging_clock_active {
		pins_cmd_dat {
			pinmux = <PINMUX_GPIO95__FUNC_GPIO95>;
			slew-rate = <0>;
			bias-pull-up;
		};
	};

	charging_clock_sleep: charging_clock_sleep {
		pins_cmd_dat {
			pinmux = <PINMUX_GPIO95__FUNC_GPIO95>;
			slew-rate = <0>;
			bias-pull-down;
		};
	};

	charging_data_active: charging_data_active {
		pins_cmd_dat {
			pinmux = <PINMUX_GPIO94__FUNC_GPIO94>;
			slew-rate = <0>;
			bias-pull-down;
		};
	};

	charging_data_sleep: charging_data_sleep {
		pins_cmd_dat {
			pinmux = <PINMUX_GPIO94__FUNC_GPIO94>;
			slew-rate = <0>;
			bias-pull-down;
		};
	};

	charging_reset_active: charging_reset_active {
		pins_cmd_dat {
			pinmux = <PINMUX_GPIO189__FUNC_GPIO189>;
			slew-rate = <1>;
			bias-pull-down;
		};
	};

	charging_reset_sleep: charging_reset_sleep {
		pins_cmd_dat {
			pinmux = <PINMUX_GPIO189__FUNC_GPIO189>;
			slew-rate = <1>;
			bias-pull-up;
		};
	};

	mps_otg_en_active: mps_otg_en_active {
		pins_cmd_dat {
			pinmux = <PINMUX_GPIO129__FUNC_GPIO129>;
			slew-rate = <1>;
			bias-pull-up;
		};
	};

	mps_otg_en_sleep: mps_otg_en_sleep {
		pins_cmd_dat {
			pinmux = <PINMUX_GPIO129__FUNC_GPIO129>;
			slew-rate = <1>;
			bias-pull-down;
		};
	};

	mps_otg_en_default: mps_otg_en_default {
		pins_cmd_dat {
			pinmux = <PINMUX_GPIO129__FUNC_GPIO129>;
			slew-rate = <1>;
			bias-pull-down;
		};
	};

	charge_pump_hwid_active: charge_pump_hwid_active {
		pins_cmd_dat {
			pinmux = <PINMUX_GPIO185__FUNC_GPIO185>;
			input-enable;
			slew-rate = <0>;
			bias-pull-up = <MTK_PUPD_SET_R1R0_10>;
		};
	};

	charge_pump_hwid_sleep: charge_pump_hwid_sleep {
		pins_cmd_dat {
			pinmux = <PINMUX_GPIO185__FUNC_GPIO185>;
			input-enable;
			slew-rate = <0>;
			bias-pull-down = <MTK_PUPD_SET_R1R0_10>;
		};
	};

	charge_pump_hwid_default: charge_pump_hwid_default {
		pins_cmd_dat {
			pinmux = <PINMUX_GPIO185__FUNC_GPIO185>;
			input-enable;
			slew-rate = <0>;
			bias-disable;
		};
	};
};

&lk_charger {
	charger_by_buckboost;
	support_tuv_authentication;
	max_charger_voltage = <9900000>;
};

&phy_tuning {
	compatible = "mediatek,phy_tuning";
	u2_vrt_ref = <6>;
	u2_term_ref = <6>;
	u2_enhance = <2>;

	u2_vrt_ref_host = <6>;
	u2_term_ref_host = <6>;
	u2_enhance_host = <2>;
};

&mt6360_pmu {
	core {
		sda_sizesel = <3>;
		sda_drvsrsel = <1>;
	};
	chg {
		support_hvdcp;
	};
};

&bat_gm30 {
	FUELGAGUE_APPLY = <(0)>;
	DISABLE_MTKBATTERY = <(1)>;
};

&i2c7 {
	pinctrl-names = "i2c-state", "output-low-state";
	pinctrl-0 = <&i2c7_i2c_state>;
	pinctrl-1 = <&i2c7_output_low_state>;
};
&pio {
	i2c7_i2c_state: i2c7_sda_i2c_state {
		pins_cmd_dat {
			pinmux = <PINMUX_GPIO125__FUNC_SDA7>;
			slew-rate = <0>;
			bias-disable;
		};
	};
	i2c7_output_low_state: i2c7_sda_output_low_state {
		pins_cmd_dat {
			pinmux = <PINMUX_GPIO125__FUNC_GPIO125>;
			slew-rate = <1>;
			output-low;
		};
	};
};

/* chagrge end */
